[part 1 of 6: packages /MVCU_AutoGenPkg/MVCU/Pck_AutoGen_Sw/ApplicationDataTypes to /MVCU_AutoGenPkg/MVCU/Pck_AutoGen_Sw/Components]
AUTOSAR XML (schema 4-2-2)
package /MVCU_AutoGenPkg/MVCU/Pck_AutoGen_Sw/ApplicationDataTypes
  2084 x app type, all with category=VALUE, sw-calibration-access=READ-ONLY:
    DT_DT_MCUM_CRC_135
    DT_DT_MCUM_RollingCounter_135
    DT_DT_MCUM_LDC_SWInfo
    DT_DT_MCUM_LDC_MTarOut_FA
    DT_DT_MCUM_LDC_MTarOut_RA
    DT_DT_MCUM_LDC_Available_FA
    DT_DT_MCUM_LDC_OperationMode_FA
    DT_DT_MCUM_LDC_Available_RA
    DT_DT_MCUM_LDC_OperationMode_RA
    DT_DT_MCUM_RTE_Exchange_Signal_Status
    DT_DT_MCUM_MTarIn_FA
    DT_DT_MCUM_MTarIn_RA
    DT_DT_MCUM_InputQF_FA
    DT_DT_MCUM_InputQF_RA
    DT_DT_IBC_CRC_136
    DT_DT_IBC_RollingCounter_136
    DT_DT_IBC_ModeMinEDrvTar_FA
    DT_DT_IBC_ModeMinEDrvTar_RA
    DT_DT_IBC_ModeMaxEDrvTar_FA
    DT_DT_IBC_ModeMaxEDrvTar_RA
    DT_DT_IBC_torque_distribution_RA_Vaild
    DT_DT_IBC_torque_distribution_RA
    DT_DT_IBC_mTar_FA
    DT_DT_IBC_mTar_RA
    DT_DT_IBC_iLDC_SWInfo
    DT_DT_IBC_Variant_Signal
    DT_DT_IBC_dTCS_VehBrkCor
    DT_DT_IBC_nTarMax_FA
    DT_DT_IBC_nTarMax_RA
    DT_DT_IBC_nTarMin_FA
    DT_DT_IBC_nTarMin_RA
    DT_DT_EVCC_DCAC_ChgMode
    DT_DT_EVCC_CP_status
    DT_DT_EVCC_CPDutyCycleValue
    DT_DT_EVCC_EVSEMaximumCurrentLimit
    DT_DT_EVCC_EVSEMaximumPowerLimit
    DT_DT_ICU_CRC_24C
    DT_DT_ICU_PHEVMode
    DT_DT_ICU_RollingCounter_24C
    DT_DT_ICU_TotalOdometerkm
    DT_DT_ICU_AccelerationMode
    DT_DT_ICU_REMode
    DT_DT_ICU_CreepMode
    DT_DT_ICU_EnergyRecoveryMode
    DT_DT_MCUS_CRC_DB
    DT_DT_MCUS_Clutch_2_Fault
    DT_DT_MCUS_Clutch_1_Fault
    DT_DT_MCUS_Clutch_2_WarningLevel
    DT_DT_MCUS_Clutch_1_WarningLevel
    DT_DT_MCUS_Clutch_2_Pos
    DT_DT_MCUS_Clutch_1_Pos
    DT_DT_MCUS_RollingCounter_DB
    DT_DT_MCUS_WarningLevel
    DT_DT_MCUS_SelfCheckSts
    DT_DT_MCUS_DrvMotorWorkSts
    DT_DT_MCUS_PowerReduceSts
    DT_DT_MCUS_SystemError
    DT_DT_MCUS_LVSystemError
    DT_DT_MCUS_MotorTempAlarm
    DT_DT_MCUS_HVSystemError
    DT_DT_MCUS_SeriousWarning_Level
    DT_DT_MCUS_CtrlModeVD
    DT_DT_MCUS_WaterPumpLevlReq
    DT_DT_MCUS_MotorTemp
    DT_DT_MCUS_IGBTTemp
    DT_DT_MCUS_InletTemp
    DT_DT_MCUS_DrvMotorRPM
    DT_DT_MCUS_ActualTorqueFB
    DT_DT_MCUS_HWRdcFault
    DT_DT_MCUS_HighVoltPowerOffReq
    DT_DT_MCUS_HVILSts
    DT_DT_MCUS_DragSts
    DT_DT_MCUS_CtrlMode
    DT_DT_MCUS_MILlampReq
    DT_DT_MCUS_DrvMotorRPMVD
    DT_DT_MCUS_ActualTorqueFBVD
    DT_DT_MCUS_MaxTorqueAllow
    DT_DT_MCUS_MaxSpeedAllow
    DT_DT_MCUS_ActiveReleaseSts
    DT_DT_MCUS_MinTorqueAllow
    DT_DT_MCUS_MainWireVolt
    DT_DT_MCUS_MainWireCurr
    DT_DT_MCUS_Clutch_Pos
    DT_DT_MCUS_Clutch_Fault
    DT_DT_MCUS_TMS_FrMotSelfHeatEnSts
    DT_DT_MCUS_TMS_FrMotSelfHeatLvlFb
    DT_DT_MCUS_HeatPwrAval
    DT_DT_DelayIden_Rslt_Avg
    DT_DT_DelayIden_OverRange
    DT_DT_DelayIden_Iden_Finish
    DT_DT_DelayIden_Write_Finish
    DT_DT_DelayIden_Rslt_U
    DT_DT_DelayIden_Rslt_V
    DT_DT_DelayIden_Rslt_W
    DT_DT_GainIden_Is_Samp_U
    DT_DT_GainIden_Rslt_U
    DT_DT_GainIden_OverRange
    DT_DT_GainIden_Is_Samp_V
    DT_DT_GainIden_Rslt_V
    DT_DT_GainIden_Iden_Finish
    DT_DT_GainIden_Is_Samp_W
    DT_DT_GainIden_Rslt_W
    DT_DT_GainIden_Write_Finish
    DT_DT_GainIden_Curr_Peak_U
    DT_DT_GainIden_Curr_Peak_V
    DT_DT_GainIden_Curr_Peak_W
    DT_DT_CurrLoad_CurExt_U
    DT_DT_CurrLoad_CurExt_V
    DT_DT_CurrLoad_CurExt_W
    DT_DT_CurrLoad_offset_Iu
    DT_DT_CurrLoad_offset_Iv
    DT_DT_CurrLoad_offset_Iw
    DT_DT_MCUMR_DelayIden_Rslt_Avg
    DT_DT_MCUMR_DelayIden_OverRange
    DT_DT_MCUMR_DelayIden_Iden_Finish
    DT_DT_MCUMR_DelayIden_Write_Finish
    DT_DT_MCUMR_DelayIden_Rslt_U
    DT_DT_MCUMR_DelayIden_Rslt_V
    DT_DT_MCUMR_DelayIden_Rslt_W
    DT_DT_MCUMR_GainIden_Is_Samp_U
    DT_DT_MCUMR_GainIden_Rslt_U
    DT_DT_MCUMR_GainIden_OverRange
    DT_DT_MCUMR_GainIden_Is_Samp_V
    DT_DT_MCUMR_GainIden_Rslt_V
    DT_DT_MCUMR_GainIden_Iden_Finish
    DT_DT_MCUMR_GainIden_Is_Samp_W
    DT_DT_MCUMR_GainIden_Rslt_W
    DT_DT_MCUMR_GainIden_Write_Finish
    DT_DT_MCUMR_GainIden_Curr_Peak_U
    DT_DT_MCUMR_GainIden_Curr_Peak_V
    DT_DT_MCUMR_GainIden_Curr_Peak_W
    DT_DT_MCUMR_CurrLoad_CurExt_U
    DT_DT_MCUMR_CurrLoad_CurExt_V
    DT_DT_MCUMR_CurrLoad_CurExt_W
    DT_DT_MCUMR_CurrLoad_offset_Iu
    DT_DT_MCUMR_CurrLoad_offset_Iv
    DT_DT_MCUMR_CurrLoad_offset_Iw
    DT_DT_BCM_VCU_Authentication_MAC_B{0..15}
    DT_DT_ECM_UDS_PhyReq_Byte{0..7}
    DT_DT_MCUM_Id_Ref
    DT_DT_MCUM_Iq_Ref
    DT_DT_MCUM_Id_Fb
    DT_DT_MCUM_Iq_Fb
    DT_DT_MCUM_Torque_Ref
    DT_DT_MCUM_R_Id_Ref
    DT_DT_MCUM_R_Iq_Ref
    DT_DT_MCUM_R_Id_Fb
    DT_DT_MCUM_R_Iq_Fb
    DT_DT_MCUM_R_Torque_Ref
    DT_DT_MCUM_Vd_Ref
    DT_DT_MCUM_Vq_Ref
    DT_DT_MCUM_Id_LookUp
    DT_DT_MCUM_Iq_LookUp
    DT_DT_MCUM_Spd_Delta
    DT_DT_MCUM_Us_Out
    DT_DT_MCUM_Torque_PwrEst
    DT_DT_MCUM_UserDefine_50ms
    DT_DT_MCUM_Torque_ExtChar
    DT_DT_MCUM_Damp_CompTorque
    DT_DT_MCUM_Damp_CompCoeff
    DT_DT_MCUM_Damp_State
    DT_DT_MCUM_PWM_State
    DT_DT_MCUM_JuncTemp_Max
    DT_DT_MCUM_JuncLoss_Max
    DT_DT_MCUM_CurrAmp_Comp
    DT_DT_MCUM_CurrTheta_Comp
    DT_DT_MCUM_RawSinCorr
    DT_DT_MCUM_RawCosCorr
    DT_DT_MCUM_LUT_Spd
    DT_DT_MCUM_R_HighVoltPowerOffReq
    DT_DT_MCUM_R_MaxTorqueAllow
    DT_DT_MCUM_R_MaxSpeedAllow
    DT_DT_MCUM_R_MinTorqueAllow
    DT_DT_MCUM_R_MotorTemp
    DT_DT_MCUM_R_IGBTTemp
    DT_DT_MCUM_R_InletTemp
    DT_DT_MCUM_R_HeatPwrAllwd
    DT_DT_MCUM_R_HeatFdBck
    DT_DT_MCUM_R_HeatPwrAct
    DT_DT_MCUM_R_HeatPwrMax
    DT_DT_MCUM_R_HeatPwrAval
    DT_DT_MCUM_R_Vd_Ref
    DT_DT_MCUM_R_Vq_Ref
    DT_DT_MCUM_R_Id_LookUp
    DT_DT_MCUM_R_Iq_LookUp
    DT_DT_MCUM_R_Spd_Delta
    DT_DT_MCUM_R_Us_Out
    DT_DT_MCUM_R_Torque_PwrEst
    DT_DT_MCUM_R_UserDefine_50ms
    DT_DT_MCUM_R_Torque_ExtChar
    DT_DT_MCUM_R_Damp_CompTorque
    DT_DT_MCUM_R_Damp_CompCoeff
    DT_DT_MCUM_R_Damp_State
    DT_DT_MCUM_R_PWM_State
    DT_DT_MCUM_R_JuncTemp_Max
    DT_DT_MCUM_R_JuncLoss_Max
    DT_DT_MCUM_R_CurrAmp_Comp
    DT_DT_MCUM_R_CurrTheta_Comp
    DT_DT_MCUM_R_RawSinCorr
    DT_DT_MCUM_R_RawCosCorr
    DT_DT_MCUM_R_LUT_Spd
    DT_DT_MCUM_R_StatorTemp_1
    DT_DT_MCUM_R_L2TqAct
    DT_DT_MCUM_R_EOPSw
    DT_DT_MCUM_R_StatorTemp_2
    DT_DT_MCUM_R_IGBTTemp_U
    DT_DT_MCUM_R_IGBTTemp_V
    DT_DT_MCUM_R_IGBTTemp_W
    DT_DT_MCUM_R_Power_15V
    DT_DT_MCUM_R_Offset_IU
    DT_DT_MCUM_R_Offset_IV
    DT_DT_MCUM_R_Offset_IW
    DT_DT_MCUM_R_MainSt_State
    DT_DT_MCUM_R_Derate_Reason
    DT_DT_MCUM_R_PWM_Freq_kHz
    DT_DT_MCUM_R_PWMEn_State
    DT_DT_MCUM_R_DrvPwrEn_Out_State
    DT_DT_MCUM_R_NVM_RslvrZeroRFault
    DT_DT_MCUM_R_Rotor_Position
    DT_DT_MCUM_R_PosTransduserFaultCode
    DT_DT_MCUM_R_NVM_RslvrDirRFault
    DT_DT_MCUM_R_NVM_RslvrDelayRFault
    DT_DT_MCUM_R_NVM_RslvrParamRFault
    DT_DT_MCUM_R_NVM_HallGainRFault
    DT_DT_MCUM_R_NVM_HallDelayRFault
    DT_DT_MCUM_R_NVM_IGBTTypeRFault
    DT_DT_MCUM_R_ASC_EntryCount
    DT_DT_MCUM_R_Spd_Turn
    DT_DT_MCUM_R_LUT_Spd_Max
    DT_DT_MCUM_R_EOP_Speed
    DT_DT_MCUM_R_EOP_IqFb
    DT_DT_MCUM_R_EOP_IqRef
    DT_DT_MCUM_R_EOP_DCVolt
    DT_DT_MCUM_R_EOP_DCCurr
    DT_DT_MCUM_R_EOP_Temp
    DT_DT_MCUM_R_EOP_State
    DT_DT_MCUM_R_EOP_FaultCode
    DT_DT_MCUM_R_HWFault_RstCnt
    DT_DT_MCUM_R_HWFoB_RstCnt
    DT_DT_MCUM_R_HWFoT_RstCnt
    DT_DT_MCUM_R_HWDrvUV_RstCnt
    DT_DT_MCUM_R_HWRdc_RstCnt
    DT_DT_MCUM_R_HWOC_RstCnt
    DT_DT_MCUM_R_HWOV_RstCnt
    DT_DT_MCUM_R_L2agRtrElecDiff
    DT_DT_MCUM_R_500usOverTime_Cnt
    DT_DT_MCUM_R_5msOverTime_Cnt
    DT_DT_MCUM_R_CpldRest_TimeOut_flag
    DT_DT_MCUM_R_DrvPCBCurr
    DT_DT_MCUM_R_EOL_StateMachine
    DT_DT_MCUM_R_CpldRest_ASC_Flag
    DT_DT_MCUM_R_LimSpdTorFlag
    DT_DT_MCUM_R_PWM_Err_Count
    DT_DT_MCUM_R_RDC_Reset_Count
    DT_DT_MCUM_R_ASC_Stop_Flag
    DT_DT_MCUM_R_ASC_Soft_Exiting_Flag
    DT_DT_MCUM_R_Vbus_ServeLowChkEn
    DT_DT_MCUM_R_EOP_BlockErr_IsLim_Flag
    DT_DT_MCUM_R_IdqErrCount
    DT_DT_MCUM_R_MotSelfHeat_EnSts
    DT_DT_MCUM_R_MotBlockHeat_LvlFb
    DT_DT_MCUM_R_MotRotaryHeat_LvlFb
    DT_DT_MCUM_R_MotSelfHeat_DropLvlFb
    DT_DT_MCUM_R_MotSelfHeat_DropLvlRsn
    DT_DT_MCUM_R_MotBlockHeat_CurAngle
    DT_DT_MCUM_R_MotBlockHeat_CurMag
    DT_DT_MCUM_R_UserDefine_Byte{1..4}
    DT_DT_MCUM_R_UserDefine_Word{1..3}
    DT_DT_VCU_MotSelfHeatPwrFb
    DT_DT_VCU_MotSelfHeatLvlFb
    DT_DT_VCU_MCUMWaterPumpLevlReq
    DT_DT_VCU_MCUSWaterPumpLevlReq
    DT_DT_VCU_HeatPwrAval
    DT_DT_VCU_MotSelfHeatAllwd
    DT_DT_VCU_MMotSelfHeatEnReq
    DT_DT_VCU_MMotSelfHeatLvlReq
    DT_DT_VCU_SMotSelfHeatEnReq
    DT_DT_VCU_SMotSelfHeatLvlReq
    DT_DT_Debug_MCU_CRC_CA
    DT_DT_Debug_MCU_RollingCounter_CA
    DT_DT_Debug_MCU_WarningLevel
    DT_DT_Debug_MCU_SelfCheckSts
    DT_DT_Debug_MCU_DrvMotorWorkSts
    DT_DT_Debug_MCU_PowerReduceSts
    DT_DT_Debug_MCU_DrvMotorRPM
    DT_DT_Debug_MCU_ActualTorqueFB
    DT_DT_Debug_MCU_HWRdcFault
    DT_DT_Debug_MCU_HighVoltPowerOffReq
    DT_DT_Debug_MCU_HVILSts
    DT_DT_Debug_MCU_DragSts
    DT_DT_Debug_MCU_CtrlMode
    DT_DT_Debug_MCU_MILlampReq
    DT_DT_Debug_MCU_DrvMotorRPMVD
    DT_DT_Debug_MCU_ActualTorqueFBVD
    DT_DT_Debug_MCU_MaxTorqueAllow
    DT_DT_Debug_MCU_MaxSpeedAllow
    DT_DT_Debug_MCU_ActiveReleaseSts
    DT_DT_Debug_MCU_DCChargRelaySts
    DT_DT_Debug_MCUM_MinTorqueAllow
    DT_DT_Debug_MCU_MainWireVolt
    DT_DT_Debug_MCU_MainWireCurr
    DT_DT_Debug_MCUM_TMS_MotSelfHeatEnSts
    DT_DT_Debug_MCUM_TMS_MotSelfHeatLvlFb
    DT_DT_Debug_MCUM_RPowerReduceSts
    DT_DT_Debug_MCUM_HeatPwrAval
    DT_DT_Debug_MCUM_RCtrlMode
    DT_DT_Debug_MCUM_RWarningLevel
    DT_DT_Debug_MCUM_RSelfCheckSts
    DT_DT_Debug_MCUM_RDrvMotorWorkSts
    DT_DT_Debug_MCUM_RCtrlModeVD
    DT_DT_Debug_MCUM_RHWRdcFault
    DT_DT_Debug_MCUM_RDrvMotorRPMVD
    DT_DT_Debug_MCUM_RActualTorqueFBVD
    DT_DT_Debug_MCUM_RDrvMotorRPM
    DT_DT_Debug_MCUM_RActualTorqueFB
    DT_DT_IBS_CRC_225
    DT_DT_IBS_RollingCounter_225
    DT_DT_IBS_Warning_Level
    DT_DT_ADDC_CRC_84
    DT_DT_ADDC_APS_AVHReq
    DT_DT_ADDC_APS_HoldSts
    DT_DT_ADDC_APSTargetTrqBrkVD
    DT_DT_ADDC_APSTargetTrqBrk
    DT_DT_ADDC_APSTargetTrqVD
    DT_DT_ADDC_APSTargetTrq
    DT_DT_ADDC_safety_valid
    DT_DT_ADDC_rearsafety_level
    DT_DT_ADDC_frontsafety_level
    DT_DT_ADDC_rightsafety_level
    DT_DT_ADDC_leftsafety_level
    DT_DT_ADDC_RollingCounter_84
    DT_DT_ADDC_APS_EnableReq
    DT_DT_ADDC_APS_WorkSts
    DT_DT_ADDC_APS_PDCVehicleDirectCtlVD
    DT_DT_ADDC_APS_VehicleSpeedCtlVD
    DT_DT_ADDC_APS_PDC_VehicleDirectCtl
    DT_DT_ADDC_APS_PDC_SWAngCtl
    DT_DT_ADDC_APS_ParkingReq
    DT_DT_ADDC_APS_EmergenceBrake
    DT_DT_ADDC_APS_TargetAccVD
    DT_DT_ADDC_APS_TargetAcc
    DT_DT_ADDC_APS_VehicleSpeedCtl
    DT_DT_ADDC_APS_DecToStop
    DT_DT_ADDC_APS_Driveoff_Request
    DT_DT_ADDC_APS_FuncType
    DT_DT_ADDC_APS_Available
    DT_DT_IVI_Year
    DT_DT_IVI_Month
    DT_DT_IVI_Data
    DT_DT_IVI_Hour
    DT_DT_IVI_Minute
    DT_DT_IVI_Second
    DT_DT_DCDC_CRC_324
    DT_DT_DCDC_RollingCounter_324
    DT_DT_DCDC_WorkSts
    DT_DT_DCDC_Under_Output_Voltage
    DT_DT_DCDC_Over_Output_Voltage
    DT_DT_DCDC_Under_Input_Voltage
    DT_DT_DCDC_Over_Input_Voltage
    DT_DT_DCDC_Over_Input_Current
    DT_DT_DCDC_Real_Output_Current
    DT_DT_DCDC_Real_Output_Voltage
    DT_DT_DCDC_Real_Input_Current
    DT_DT_DCDC_Real_Input_Voltage
    DT_DT_DCDC_Derating
    DT_DT_DCDC_Hardware_Fault_Flag
    DT_DT_CDU_ACChg_HIVSts
    DT_DT_CDU_OBC_OverTemp
    DT_DT_CDU_SelfCheckSt
    DT_DT_CDU_HV_HIVSts
    DT_DT_FSC_CRC_142
    DT_DT_FSC_RollingCounter_142
    DT_DT_FSC_LCC_Mode
    DT_DT_MotClb_FaultCode{1..8}
    DT_DT_MotClb_OfsApply
    DT_DT_MCUMR_MotClb_FaultCode{1..8}
    DT_DT_MCUMR_MotClb_OfsApply
    DT_DT_EOL_ModeCMD_Data{0..5}
    DT_DT_EOL_ModeCMD_Enable
    DT_DT_EOL_ModeCMD_Check
    DT_DT_EOL_GainIden_UsApply
    DT_DT_EOL_MotClb_CtrlMode
    DT_DT_MotClb_OfsSet
    DT_DT_EOL_MotClb_IsCMD
    DT_DT_EOL_MotClb_ThetaCMD
    DT_DT_EOL_frqsync
    DT_DT_EOL_MotClb_Enable
    DT_DT_EOL_ActiveReleaseCmd
    DT_DT_MotClb_OfsAdjEn
    DT_DT_EOL_Asc_CMD
    DT_DT_EOL_PosDly_SnsrSupplier
    DT_DT_FstRcrd_Enable
    DT_DT_GainIden_CurrRMS_Ref_U
    DT_DT_GainIden_CurrRMS_Ref_V
    DT_DT_GainIden_CurrRMS_Ref_W
    DT_DT_MCUMR_EOL_GainIden_UsApply
    DT_DT_MCUMR_EOL_MotClb_CtrlMode
    DT_DT_MCUMR_MotClb_OfsSet
    DT_DT_MCUMR_EOL_MotClb_IsCMD
    DT_DT_MCUMR_EOL_MotClb_ThetaCMD
    DT_DT_MCUMR_EOL_frqsync
    DT_DT_MCUMR_EOL_MotClb_Enable
    DT_DT_MCUMR_EOL_ActiveReleaseCmd
    DT_DT_MCUMR_MotClb_OfsAdjEn
    DT_DT_MCUMR_EOL_Asc_CMD
    DT_DT_MCUMR_EOL_PosDly_SnsrSupplier
    DT_DT_MCUMR_FstRcrd_Enable
    DT_DT_MCUMR_GainIden_CurrRMS_Ref_U
    DT_DT_MCUMR_GainIden_CurrRMS_Ref_V
    DT_DT_MCUMR_GainIden_CurrRMS_Ref_W
    DT_DT_MCUS_CRC_14
    DT_DT_MCUS_RollingCounter_14
    DT_DT_MCUS_DrvMotorRPM_prvt
    DT_DT_MCUS_ActualTorqueFB_prvt
    DT_DT_MCUS_DrvMotorRPMVD_prvt
    DT_DT_MCUS_ActualTorqueFBVD_prvt
    DT_DT_U16_CMD{1..4}
    DT_DT_S16_CMD{1..4}
    DT_DT_R16_CMD{1..4}
    DT_DT_U8_CMD{1..8}
    DT_DT_OBC_CRC_316
    DT_DT_OBC_RollingCounter_316
    DT_DT_OBC_WorkSts
    DT_DT_OBC_StartSts
    DT_DT_OBC_DCSts
    DT_DT_OBC_ACChargeOutputSts
    DT_DT_OBC_DCVolt
    DT_DT_OBC_HardwareSts
    DT_DT_OBC_DCCurr
    DT_DT_OBC_ACVolt
    DT_DT_OBC_ACCurr
    DT_DT_OBC_CCConnectSts
    DT_DT_OBC_CPDutyCycleFault
    DT_DT_OBC_CPDutyCycleValue
    DT_DT_OBC_ACMaxPower
    DT_DT_OBC_ACPowerState
    DT_DT_LMC_CRC_FA
    DT_DT_LMC_RollingCounter_FA
    DT_DT_LMC_EngTorqDec_Main
    DT_DT_LMC_EngTorqDecActive_Main
    DT_DT_LMC_AMM_St
    DT_DT_LMC_EngTorqInc_Main
    DT_DT_LMC_EngTorqIncActive_Main
    DT_DT_LMC_EngTorqDec_Sub
    DT_DT_LMC_EngTorqDecActive_Sub
    DT_DT_LMC_EngTorqInc_Sub
    DT_DT_LMC_EngTorqIncActive_Sub
    DT_DT_LMC_CRC_18C
    DT_DT_LMC_RollingCounter_18C
    DT_DT_LMC_TqTotalBrakeTorque
    DT_DT_LMC_TqTotalBrakeTorque_Valid
    DT_DT_LMC_CmpUTurnLockwhists
    DT_DT_GW_CRC_3B1
    DT_DT_GW_RollingCounter_3B1
    DT_DT_GW_ACU_FLSeatBeltRSt
    DT_DT_GW_ACU_FRSeatBeltRSt
    DT_DT_GW_IBC_EPB_Status
    DT_DT_GW_ACU_TotalCrashOutputSts
    DT_DT_GW_BZCU_DCChgExitTemp_Pos
    DT_DT_GW_BZCU_DCChgExitTemp_Neg
    DT_DT_GW_BZCU_ACChgExitTemp_Pos
    DT_DT_GW_BZCU_FuelTankSts
    DT_DT_GW_BZCU_LBMS_VoltA
    DT_DT_GW_BZCU_ACChgExitTemp_Neg
    DT_DT_GW_BZCU_FuelTankStsLockSts
    DT_DT_GW_BZCU_FuelTankLockCtrl
    DT_DT_GW_BZCU_ACChgLockSts
    DT_DT_GW_RZCU_Cabin_220Vconnect_Sts
    DT_DT_GW_BZCU_Cab_220VRelay_CtrlSts
    DT_DT_GW_BZCU_Cab_PDU220VRelay_CtrlSts
    DT_DT_GW_BZCU_Cabin_220VRelay_CtrlSts
    DT_DT_GW_BZCU_Cab_220Vconnect_Sts
    DT_DT_GW_TBOXSOC_Altitude
    DT_DT_VCU_EolCfg_ESC
    DT_DT_VCU_IMMOKeyWriteCnt
    DT_DT_VCU_AbStartupFlag
    DT_DT_VCU_AbResetFlag
    DT_DT_VCU_AbResetlnitFinish
    DT_DT_VCU_EolCfg_EPB
    DT_DT_VCU_EolCfg_AEB
    DT_DT_VCU_EolCfg_InverterFunc
    DT_DT_VCU_EolCfg_APS
    DT_DT_VCU_EolCfg_VehiModels
    DT_DT_VCU_EolCfg_SpdLmtVal
    DT_DT_VCU_EolCfg_WheelType
    DT_DT_VCU_EolCfg_Curise
    DT_DT_VCU_REStartReq
    DT_DT_VCU_REStopReq
    DT_DT_VCU_EolCfg_VehiType
    DT_DT_VCU_EolCfg_MotPwr
    DT_DT_VCU_Vehicle_NVHPwrLimitVal
    DT_DT_VCU_EolCfg_MotDrvStructure
    DT_DT_VCU_WLTCModeFlag
    DT_DT_VCU_EolCfg_RudderDir
    DT_DT_VCU_EolCfg_DCChgRelayPos
    DT_DT_VCU_EolCfg_FPTCIL
    DT_DT_VCU_PWakeupSt
    DT_DT_VCU_SpdLimitReason
    DT_DT_BSW_VertifySts
    DT_DT_VCU_InterAllowEngStart
    DT_DT_VCU_EngineOff_Flag
    DT_DT_VCU_EngineStopAllow
    DT_DT_VCU_EmergencyStopReq
    DT_DT_VCU_EngineAllowStop
    DT_DT_VCU_REVehiWheelTrqReq
    DT_DT_VCU_REHighPerformVehiPwr
    DT_DT_VCU_REPwrDampingFactor
    DT_DT_VCU_REDrvTarPwrFit
    DT_DT_VCU_AdditionalPwrVal
    DT_DT_VCU_VehichRealPwDown
    DT_DT_VCU_IMMOStsResult
    DT_DT_VCU_IMMOStateMachine
    DT_DT_VCU_ShowCarModeNvmResult
    DT_DT_VCU_DeliveryModeNvmData
    DT_DT_VCU_AccPedFaultLvNvmResult
    DT_DT_VCU_VehicleConfigNvmResult
    DT_DT_VCU_EngRunTimeNvmResult
    DT_DT_VCU_FuelConsumption
    DT_DT_VCU_SVSLamp
    DT_DT_VCU_MilLamp
    DT_DT_VCU_SinglePedalSts_ID514
    DT_DT_VCU_GearLevelPosFault_ID514
    DT_DT_VCU_EngineStartFailure_ID514
    DT_DT_VCU_ParkBeforeFuelup
    DT_DT_VCU_REsystemFaultSts_ID514
    DT_DT_VCU_EngineRunAllowFlg_ID514
    DT_DT_VCU_InverterTip
    DT_DT_VCU_EMSRepairModeSts
    DT_DT_VCU_FuelTankFlapSts
    DT_DT_VCU_REsystemSts_ID514
    DT_DT_VCU_PowerModeAllow
    DT_DT_VCU_PowerModeSwitchMsg
    DT_DT_VCU_HighVoltFailed_M
    DT_DT_VCU_HighVoltFailed_S
    DT_DT_VCU_BrakeBeforeGear
    DT_DT_VCU_ParkBeforeGear
    DT_DT_VCU_GearBeforDriving
    DT_DT_VCU_UnlockBeforeDriving
    DT_DT_VCU_PreventSliding
    DT_DT_VCU_MMErrorSts
    DT_DT_VCU_ShowCarModeSts
    DT_DT_VCU_PGearFlashSts
    DT_DT_VCU_ACConnectSts
    DT_DT_VCU_DcChgPwrSts
    DT_DT_VCU_DriverAssistProhibitSts_ID514
    DT_DT_VCU_MilLampRequest_ID514
    DT_DT_VCU_CcmHvilInSigFreq_FB
    DT_DT_VCU_CcmHvilInSigDuty_FB
    DT_DT_VCU_FuelDectionModeSts
    DT_DT_VCU_EnergyCtrlMode
    DT_DT_VCU_VehSpdLimtRemind_ID514
    DT_DT_VCU_TurtleLamp
    DT_DT_VCU_EngLongTimeStartReq
    DT_DT_GW_CRC_13A
    DT_DT_GW_RollingCounter_13A
    DT_DT_GW_IBC_VehicleSpeed
    DT_DT_GW_IBC_VehicleSpeedVD
    DT_DT_GW_IBC_AVHStatus
    DT_DT_GW_IBC_RAB_Avatiable
    DT_DT_GW_IBC_RAB_Active
    DT_DT_GW_IBC_FLWheelSpeedKPH
    DT_DT_GW_IBC_FRWheelSpeedKPH
    DT_DT_GW_IBC_RLWheelSpeedKPH
    DT_DT_GW_IBC_RRWheelSpeedKPH
    DT_DT_GW_IBC_FLWheelDirection
    DT_DT_GW_IBC_FRWheelDirection
    DT_DT_GW_IBC_RLWheelDirection
    DT_DT_GW_IBC_RRWheelDirection
    DT_DT_GW_IBC_FLWheelSpeedVD
    DT_DT_GW_IBC_FRWheelSpeedVD
    DT_DT_GW_IBC_RLWheelSpeedVD
    DT_DT_GW_IBC_RRWheelSpeedVD
    DT_DT_GW_IBC_PlungerPressure_Q
    DT_DT_GW_IBC_PlungerPressure
    DT_DT_CCM_Volt
    DT_DT_CCM_RollingCounter_36A
    DT_DT_CCM_BaseState
    DT_DT_CCM_Power
    DT_DT_CCM_APTC_BscSts
    DT_DT_CCM_APTC_Power
    DT_DT_IBC_CRC_227
    DT_DT_IBC_RollingCounter_227
    DT_DT_IBC_EPB_FailStatus
    DT_DT_IBC_EPB_Status
    DT_DT_IBC_EPB_DrumMode
    DT_DT_IBC_EPB_AchievedClampForce
    DT_DT_IBC_EPB_FailureLamp
    DT_DT_IBC_EPB_ActuatorStateLeft
    DT_DT_IBC_EPB_ActuatorStateRight
    DT_DT_IBC_EPB_HostAvailabilityLeft
    DT_DT_IBC_EPB_HostAvailabilityRight
    DT_DT_Harness_igbt_temp{1..3}
    DT_DT_Harness_CoolWaterTemp
    DT_DT_Harness_V_DC
    DT_DT_Harness_PWM_DIR
    DT_DT_Harness_HVIL_State
    DT_DT_Harness_crash_err_flag
    DT_DT_Harness_KeyON
    DT_DT_Harness_HWRdc
    DT_DT_Harness_HWFoT
    DT_DT_Harness_HWVoltLower
    DT_DT_Harness_HWFoB
    DT_DT_Harness_MotorTemp1
    DT_DT_Harness_MotorTemp2
    DT_DT_Harness_I_U
    DT_DT_Harness_I_W
    DT_DT_Harness_I_V
    DT_DT_Harness_HVRelayPosVolt
    DT_DT_MCUMR_Harness_igbt_temp{1..3}
    DT_DT_MCUMR_Harness_CoolWaterTemp
    DT_DT_MCUMR_Harness_V_DC
    DT_DT_MCUMR_Harness_PWM_DIR
    DT_DT_MCUMR_Harness_HWRdc
    DT_DT_MCUMR_Harness_HWFoT
    DT_DT_MCUMR_Harness_HWVoltLower
    DT_DT_MCUMR_Harness_HWFoB
    DT_DT_MCUMR_Harness_MotorTemp1
    DT_DT_MCUMR_Harness_MotorTemp2
    DT_DT_MCUMR_Harness_I_U
    DT_DT_MCUMR_Harness_I_W
    DT_DT_MCUMR_Harness_I_V
    DT_DT_BCM_CRC_290
    DT_DT_BCM_RRDoorSts_ID290_CCAN
    DT_DT_BCM_RLDoorSts_ID290_CCAN
    DT_DT_BCM_RollingCounter_290
    DT_DT_BCM_HazardSwtSts
    DT_DT_BCM_DrOC_PPD_Status
    DT_DT_BCM_FLOC_PPD_Status
    DT_DT_BCM_FROC_PPD_Status
    DT_DT_BCM_DriverDoorSts_ID290_CCAN
    DT_DT_BCM_DriverDoorSts_VD
    DT_DT_BCM_FLDoorSts_ID290_CCAN
    DT_DT_BCM_FRDoorSts_ID290_CCAN
    DT_DT_BCM_BackDoorSts_ID290_CCAN
    DT_DT_BCM_FrontCoverSts
    DT_DT_BCM_HazardSwtOpenSts
    DT_DT_BCM_BrakeFluidLevel
    DT_DT_BCM_ON2BRelaySts_ID290_CCAN
    DT_DT_BCM_ON2CRelaySts_ID290_CCAN
    DT_DT_BCM_AlarmMode_C
    DT_DT_VCU_CRC_13
    DT_DT_VCU_RollingCounter_13
    DT_DT_VCU_SDrvRequestTorque_prvt
    DT_DT_VCU_SDrvRequestTorqueVD_prvt
    DT_DT_VCU_MCUSDampgLmtFactor_prvt
    DT_DT_VCU_VehicleDirectS_prvt
    DT_DT_VCU_VehicleDirectS_VD_prvt
    DT_DT_VCU_MCUSMaxPosDampgTrq_prvt
    DT_DT_VCU_MCUSMaxNegDampgTrq_prvt
    DT_DT_EOL_CRC_13B
    DT_DT_EOL_RollingCounter_13B
    DT_DT_EOL_VehicleSts
    DT_DT_EOL_GearLevelPosSts
    DT_DT_EOL_GearLeverValid
    DT_DT_EOL_AccPedalValid
    DT_DT_EOL_ThrottlePosition
    DT_DT_EOL_RMCUActiveReleaseCmd
    DT_DT_EOL_VehicleDirect
    DT_DT_EOL_SuppressJitterRMCURequest
    DT_DT_EOL_RDrvControlMode
    DT_DT_EOL_BrakePedalValue
    DT_DT_EOL_RMCUMaxDischargePower
    DT_DT_EOL_RMCUMaxChargePower
    DT_DT_EOL_RDrvRequestTorque
    DT_DT_EOL_RDrvRequesSpeed
    DT_DT_EOL_FDrvRequestTorque
    DT_DT_EOL_FDrvRequesSpeed
    DT_DT_EOL_FVehicleSts
    DT_DT_EOL_FDrvControlMode
    DT_DT_EOL_ON2BRelayReq
    DT_DT_EOL_VehicleDirectVD
    DT_DT_EOL_RDrvControlModeVD
    DT_DT_EOL_RDrvRequestTorqueVD
    DT_DT_EOL_RDrvRequesSpeedVD
    DT_DT_EOL_FDrvRequestTorqueVD
    DT_DT_EOL_FDrvRequesSpeedVD
    DT_DT_EOL_FDrvControlModeVD
    DT_DT_EOL_MCUMDampgLmtFactor
    DT_DT_EOL_VCU_BoostMode_Fail
    DT_DT_EOL_VCU_BoostModeSts
    DT_DT_EOL_MCUMMaxPosDampgTrq
    DT_DT_EOL_MCUMMaxNegDampgTrq
    DT_DT_TMS_MilLampReq
    DT_DT_EMS_CRC_BE
    DT_DT_EMS_RollingCounter_BE
    DT_DT_EMS_EngineSts
    DT_DT_ECM_FaultLevel
    DT_DT_ECM_ActualEngineTorqueValid
    DT_DT_ECM_EngineTorqueLoss
    DT_DT_ECM_ActualEngineTorque
    DT_DT_ECM_EngineTorqueMax
    DT_DT_ECM_EngineTorqueMin
    DT_DT_ECM_EngineSpeed
    DT_DT_ECM_EngineSpeedValid
    DT_DT_ECM_EngineStopAllow
    DT_DT_ECM_EngineOilPressureLow
    DT_DT_ECM_EngineFuleCutoffSts
    DT_DT_ECM_EngineStartedCompleted
    DT_DT_ECM_CatalystWarmUpSts
    DT_DT_ECM_CatalystWarmUpReq
    DT_DT_ECM_IdleTargetSpeed
    DT_DT_ECM_IdleActive
    DT_DT_ECM_EngineStartReq
    DT_DT_ECM_EngineStopInhibit
    DT_DT_ECM_GPFRegenlamp
    DT_DT_ECM_EngineCoolantTemp
    DT_DT_ECM_EngineCoolantTempValid
    DT_DT_ECM_FVVSts
    DT_DT_ECM_learningReq
    DT_DT_ECM_EngineIdleStateRequest
    DT_DT_ECM_EngineDFCOConditionRequest
    DT_DT_ECM_GPFRegenReq
    DT_DT_ECM_SVSLampRequest
    DT_DT_ECM_TankPressure
    DT_DT_ECM_TankPressureValid
    DT_DT_ECM_MilLampRequest
    DT_DT_ECM_ToothlearningSucValid
    DT_DT_ECM_FuelCloseLoopSts
    DT_DT_ECM_RestrictorOpenValue
    DT_DT_ECM_FuelLevelSensorValid
    DT_DT_ECM_FuelLevel
    DT_DT_ECM_SelfCheckSt
    DT_DT_ECM_PCVPipeDiagReq
    DT_DT_ECM_CalculatedLoad
    DT_DT_ECM_FuelConsumption
    DT_DT_ECM_AirPressure
    DT_DT_ECM_FanSts
    DT_DT_EPS_CRC_18D
    DT_DT_EPS_RollingCounter_18D
    DT_DT_EPS_Fault
    DT_DT_EPS_CalibrationSts
    DT_DT_EPS_FailureSts
    DT_DT_EPS_SteeringAngleValidData
    DT_DT_EPS_SteeringAngleSpeedValidData
    DT_DT_EPS_SteerWheelAngle
    DT_DT_EPS_SteerWheelRotSpd
    DT_DT_EPS_SelfCheckSt
    DT_DT_EPS_AssistanceSts
    DT_DT_GCU_CRC_BD
    DT_DT_GCU_EngineCylinderDeactivationStatus
    DT_DT_GCU_EngineFuelInhibitReq
    DT_DT_GCU_RollingCounter_BD
    DT_DT_GCU_MainWireCurr
    DT_DT_GCU_MainWireVolt
    DT_DT_GCU_SystemWarning
    DT_DT_GCU_MILlampReq
    DT_DT_GCU_MoterTemp
    DT_DT_GCU_Temp
    DT_DT_GCU_SelfCheck
    DT_DT_GCU_Warning_Level
    DT_DT_GCU_HVILSts
    DT_DT_GCU__PowerReduceSts
    DT_DT_GCU_ActualMotorRPM_VD
    DT_DT_GCU_ActualMotorTorque_VD
    DT_DT_GCU_ActualMotorTorque
    DT_DT_GCU_MaxTorque
    DT_DT_GCU_ActiveReleaseFB
    DT_DT_GCU_MAXPower
    DT_DT_GCU_TransientPower
    DT_DT_GCU_HVOffReq
    DT_DT_GCU_ControlMode
    DT_DT_GCU_Operating_Mode
    DT_DT_GCU_ActualMotorRPM
    DT_DT_BMS_WkupVolt_DC12V
    DT_DT_BMS_WkupVolt_AC12V
    DT_DT_BMS_HVPackPosRelayExternalVolt
    DT_DT_BMS_SOC_target
    DT_DT_BMS_CorrectSOEPer
    DT_DT_BMS_SOCModifyFlag
    DT_DT_BMS_BMU_SoftwareVersion
    DT_DT_VCU_VehicleSpdDirect
    DT_DT_VCU_ADM_ActualMode
    DT_DT_VCU_ADM_MainMode
    DT_DT_VCU_DeliveryModeSts
    DT_DT_VCU_VehSpdLimtRemind
    DT_DT_VCU_SinglePedalSts
    DT_DT_VCU_GearLvrChangeSts
    DT_DT_VCU_HighVoltSysSts
    DT_DT_VCU_ChrgDischrgFunSts
    DT_DT_VCU_CalibrationVersion
    DT_DT_VCU_CalibrationNumber
    DT_DT_VCU_VehicleNegTrqRspdSts
    DT_DT_VCU_SlopeEst
    DT_DT_VCU_SlopeEst_Valid
    DT_DT_VCU_WheelTrqType
    DT_DT_VCU_DriverAssistProhibitSts
    DT_DT_VCU_VacumRlySts
    DT_DT_VCU_DriveSHVILSts
    DT_DT_VCU_DriveMHVILSts
    DT_DT_VCU_DCChgHVILSts
    DT_DT_VCU_ACChgHVILSts
    DT_DT_VCU_CCMHVILSts
    DT_DT_VCU_SystemError
    DT_DT_VCU_AccPedalFaultLV
    DT_DT_VCU_HVILSysSts
    DT_DT_VCU_VacuumDegree
    DT_DT_VCU_LPedalModeSts
    DT_DT_VCU_LVSystemError
    DT_DT_VCU_HVSystemError
    DT_DT_VCU_OpeartingMode
    DT_DT_VCU_EnergyMode
    DT_DT_VCU_GearLevelPosFault
    DT_DT_VCU_BrakeSwitchSts
    DT_DT_VCU_SpdLimModeSts
    DT_DT_VCU_TrqDstrbutnPrio
    DT_DT_VCU_TrqDstrbutnTransferSts
    DT_DT_VCU_MCUMDiffProtectSts
    DT_DT_VCU_MCUSDiffProtectSts
    DT_DT_ICU_CRC_332
    DT_DT_ICU_RollingCounter_332
    DT_DT_ICU_AEB_SW
    DT_DT_ICU_ISA_controlSW
    DT_DT_ICU_SLIF_SW
    DT_DT_ICU_SLWF_SW
    DT_DT_TMS_MainMotPumpSpdResp
    DT_DT_TMS_MainMotPump_Operation_Temp
    DT_DT_TMS_MainMotPump_Operation_Current
    DT_DT_TMS_MainMotPump_Supplied_Voltage
    DT_DT_TMS_MainMotPumpErrSts
    DT_DT_IBC_CRC_184
    DT_DT_IBC_RollingCounter_184
    DT_DT_IBC_FLWheelSpeedKPH
    DT_DT_IBC_FRWheelSpeedKPH
    DT_DT_IBC_RLWheelSpeedKPH
    DT_DT_IBC_RRWheelSpeedKPH
    DT_DT_IBC_FLWheelDirection
    DT_DT_IBC_FRWheelDirection
    DT_DT_IBC_RLWheelDirection
    DT_DT_IBC_RRWheelDirection
    DT_DT_IBC_FLWheelSpeedVD
    DT_DT_IBC_FRWheelSpeedVD
    DT_DT_IBC_RLWheelSpeedVD
    DT_DT_IBC_RRWheelSpeedVD
    DT_DT_IBC_FLWheelSpeedRC
    DT_DT_IBC_FRWheelSpeedRC
    DT_DT_IBC_RLWheelSpeedRC
    DT_DT_IBC_RRWheelSpeedRC
    DT_DT_IBC_DiscTemperatureFL
    DT_DT_IBC_DiscTemperatureFLVD
    DT_DT_IBC_DiscTemperatureFR
    DT_DT_IBC_DiscTemperatureFRVD
    DT_DT_IBC_DiscTemperatureRL
    DT_DT_IBC_DiscTemperatureRLVD
    DT_DT_IBC_DiscTemperatureRR
    DT_DT_IBC_DiscTemperatureRRVD
    DT_DT_IBC_CRC_183
    DT_DT_IBC_RollingCounter_183
    DT_DT_IBC_RecuBrakeTorqueRequest
    DT_DT_IBC_RecuBrakeTorqueRequest_Q
    DT_DT_IBC_sOutputRodDriverPer_Q
    DT_DT_IBC_BrakePedalApplied_Q
    DT_DT_IBC_HydraTorqTgtAct_Q
    DT_DT_IBC_HydraTorqTgtAct
    DT_DT_IBC_BrakePedalApplied
    DT_DT_IBC_sOutputRodDriverPer
    DT_DT_IBC_HydraTorqAvailable
    DT_DT_IBC_CtrlMode
    DT_DT_IBC_QDC_HydraTorqTgt
    DT_DT_IBC_InPutRodDriver
    DT_DT_IBC_InPutRodDriver_Q
    DT_DT_IBC_SystemAssistedStatus
    DT_DT_IBC_EngTorq_VLC_Vaild
    DT_DT_IBC_EngTorq_VLC
    DT_DT_IBC_BrkTorq_VLC
    DT_DT_IBC_BrkTorq_VLC_Vaild
    DT_DT_IBC_CRC_186
    DT_DT_IBC_RollingCounter_186
    DT_DT_IBC_WheelPressureReliabilityFL
    DT_DT_IBC_WheelPressureReliabilityFR
    DT_DT_IBC_WheelPressureReliabilityRL
    DT_DT_IBC_WheelPressureReliabilityRR
    DT_DT_IBC_WheelCylinderPressure_FL
    DT_DT_IBC_WheelCylinderPressure_FR
    DT_DT_IBC_WheelCylinderPressure_RL
    DT_DT_IBC_WheelCylinderPressure_RR
    DT_DT_IBC_WheelSlipFLVD
    DT_DT_IBC_WheelSlipFRVD
    DT_DT_IBC_WheelSlipRLVD
    DT_DT_IBC_WheelSlipRRVD
    DT_DT_IBC_WheelSlipFL
    DT_DT_IBC_WheelSlipFR
    DT_DT_IBC_WheelSlipRL
    DT_DT_IBC_WheelSlipRR
    DT_DT_IBC_Slop_Pencent
    DT_DT_PTC_BscSts
    DT_DT_PTC_RollingCounter_367
    DT_DT_PTC_Fault
    DT_DT_PTC_Power
    DT_DT_PTC_HV_interlock_faultSt
    DT_DT_VCU_FaultData{0..31}
    DT_DT_GW_TCM_CRC_30B
    DT_DT_GW_TCM_RollingCounter_30B
    DT_DT_GW_TCM_ParkingSwSts
    DT_DT_GW_TCM_STATUS_Park
    DT_DT_GW_TCM_Counter_Park
    DT_DT_GW_TCM_CRC_Park
    DT_DT_GW_TCM_GearLevelSwitchSts
    DT_DT_GW_TCM_STATUS_RND
    DT_DT_GW_TCM_Counter_RND
    DT_DT_GW_TCM_CRC_RND
    DT_DT_GW_TCM_SelfCheckSt
    DT_DT_VCU_CRC_B7
    DT_DT_VCU_KeepWorkModeFlag
    DT_DT_VCU_MAI_Active
    DT_DT_VCU_MAI_Available
    DT_DT_VCU_GetCrashStsReq
    DT_DT_VCU_ADASPosTorqueCap_VD
    DT_DT_VCU_ADASPosTorqueCap
    DT_DT_VCU_RollingCounter_B7
    DT_DT_VCU_Vehicle_Warning_IDB7_CCAN
    DT_DT_VCU_VehicleSts_IDB7_CCAN
    DT_DT_VCU_PowerReduceReq
    DT_DT_VCU_ParkingReqToEPB_VD
    DT_DT_VCU_ParkingReqToEPB
    DT_DT_VCU_ACCAvailable
    DT_DT_VCU_ACCActiveSts
    DT_DT_VCU_Active_APS
    DT_DT_VCU_Available_APS
    DT_DT_VCU_ESCActive
    DT_DT_VCU_ESCTorqReqAvailability_Rear
    DT_DT_VCU_AutoHold_ibit
    DT_DT_VCU_VehicleSpeedVD
    DT_DT_VCU_CCSStatus
    DT_DT_VCU_AutoDriveRequest
    DT_DT_VCU_CCSAllow
    DT_DT_VCU_VlcHoldSts
    DT_DT_VCU_HoldReqSts
    DT_DT_VCU_HoldReqStsValid
    DT_DT_VCU_DriverAssistProhibitSts_IDB7_CCAN
    DT_DT_VCU_SpeedLimitedSts
    DT_DT_VCU_SpeedLimitedValue
    DT_DT_VCU_TheoAccePedalPercent
    DT_DT_VCU_RecuBrakeTorqueCap
    DT_DT_VCU_RecuBrakeTorqueAct
    DT_DT_VCU_TheoAccePedalValid
    DT_DT_VCU_HydraTorqTgt
    DT_DT_VCU_RecuBrakeTorqueActDrag
    DT_DT_VCU_ESCTorqReqAvailability_Frnt
    DT_DT_VCU_RecuBrakeTorqueCap_Q
    DT_DT_VCU_RecuBrakeTorqueAct_Q
    DT_DT_VCU_HydraTorqTgt_Q
    DT_DT_VCU_RecuBrakeTorqueActDrag_Q
    DT_DT_VCU_RecuBrakeTorqueTarget_Drag
    DT_DT_VCU_PreventVehSlipSts
    DT_DT_VCU_RecuBrakeTorqueTarget_Drag_Q
    DT_DT_VCU_AllMotWhlTrqFB
    DT_DT_VCU_AllMotWhlTrqFB_VD
    DT_DT_VCU_LSFC_Allow
    DT_DT_VCU_LSFC_Active
    DT_DT_VCU_MGCUWorkMode_C
    DT_DT_VCU_AllRoadSts
    DT_DT_VCU_CmpUTurnAllow
    DT_DT_VCU_CmpUTurnSts
    DT_DT_VCU_AllowCmpUTurnStartFlag
    DT_DT_VCU_CmpUTurnLockWhl
    DT_DT_VCU_CmpUTurnActAngle
    DT_DT_VCU_CmpUTurnActSpinSpd
    DT_DT_VCU_CmpUTurnFltHMI
    DT_DT_VCU_EscapeModeSts
    DT_DT_VCU_MCUSWorkFailMsg
    DT_DT_VCU_EscapeWorkFailMsg
    DT_DT_VCU_REClutchFltMsg
    DT_DT_VCU_BoostMode_Fail_C
    DT_DT_VCU_BoostModeSts_C
    DT_DT_DbgSignal{1..12}_FA
    DT_DT_DbgSignal{1..12}_RA
    DT_DT_ECM_UDS_Res_Byte{0..7}
    DT_DT_VCU_BCM_Authentication_MAC_A{0..15}
    DT_DT_VCU_BCM_Authentication_Challenge_B{0..3}
    DT_DT_TMS_MCUMHeatPwrReq
    DT_DT_TMS_MCUMHeatModEnad
    DT_DT_TMS_VCU_MotSelfHeatEnReq
    DT_DT_TMS_VCU_MotSelfHeatLvlReq
    DT_DT_ECM_SWVersionC
    DT_DT_ECM_SWVersionB
    DT_DT_ECM_SWVersionA
    DT_DT_ECM_Total_fuel_consumed
    DT_DT_IVI_CRC_331
    DT_DT_IVI_RollingCounter_331
    DT_DT_IVI_EPBRequst
    DT_DT_IVI_TerrainMatchMode
    DT_DT_IVI_LPedalModeSW
    DT_DT_IVI_AVHSw_X
    DT_DT_IVI_ESCSw_X
    DT_DT_IVI_HDCSw_X
    DT_DT_IVI_CSTSw_X
    DT_DT_IVI_AutoAllRoad
    DT_DT_IVI_CampingMode_SW
    DT_DT_IVI_BraPedMod
    DT_DT_IVI_SlowspeedSmartCtrl
    DT_DT_IVI_TrailerModeCtrl
    DT_DT_IVI_EscapeMode_SW
    DT_DT_IVI_PowerSavingModeReq
    DT_DT_IVI_SelfAdaptionDriveSW
    DT_DT_IVI_CmpUTurnStartUI
    DT_DT_IVI_CmpUTurnLockWhlUI
    DT_DT_IVI_CmpUTurnTarDirUI
    DT_DT_IVI_CmpUTurnTarAngleUI
    DT_DT_IVI_CmpUTurnReq
    DT_DT_IVI_InventerLimitOdometerkm
    DT_DT_IVI_FuelDetMode
    DT_DT_IVI_EngineIdlingMode
    DT_DT_IVI_CarWashMode
    DT_DT_IVI_CampingModeSW
    DT_DT_IVI_SpeedLimitModeSW
    DT_DT_IVI_FuelupReq
    DT_DT_IVI_FuelChgLevel
    DT_DT_IVI_FuelChgMode
    DT_DT_IVI_InventerLimitOdometerkmVD
    DT_DT_IVI_EMSRepairModeReq
    DT_DT_IVI_ForceChgModeReq
    DT_DT_IVI_ForceChgTargetSOCVD
    DT_DT_IVI_SpeedLimitModeSpeed
    DT_DT_IVI_AWDModeSW
    DT_DT_IVI_ForceChgTargetSOC
    DT_DT_BCM_VCU_Authentication_Sts
    DT_DT_BCM_PTCLossMissErr
    DT_DT_BCM_PTCRollCntErr
    DT_DT_BCM_PTCChksumErr
    DT_DT_BCM_PDUHVIL_STs
    DT_DT_BCM_Cab220VHVIL_STs
    DT_DT_BCM_Cabin220VHVIL_STs
    DT_DT_IBC_CRC_185
    DT_DT_IBC_RollingCounter_185
    DT_DT_IBC_PlungerPressure
    DT_DT_IBC_PlungerPressure_Q
    DT_DT_IBC_SimulatorPressure
    DT_DT_IBC_SimulatorPressure_Q
    DT_DT_IBC_HMI_WarningOn
    DT_DT_IBC_MIL_WarningOn
    DT_DT_IBC_LongitAcceAct
    DT_DT_IBC_LongitAcceActValid
    DT_DT_IBC_brakeFluidWarning
    DT_DT_IBC_SCM_Active
    DT_DT_IBC_SCM_Failed
    DT_DT_IBC_CDPAvailable
    DT_DT_IBC_CDPIntervention
    DT_DT_IBC_AEB_active
    DT_DT_IBC_AEBdecAvailable
    DT_DT_IBC_AVHStatus
    DT_DT_IBC_AVHAvailable
    DT_DT_IBC_HHCActive
    DT_DT_IBC_HHCFailed
    DT_DT_IBC_CDD_Available_APA
    DT_DT_IBC_CDD_Active_APA
    DT_DT_IBC_CDD_Available_ACC
    DT_DT_IBC_CDD_Active_ACC
    DT_DT_IBC_HDCStatus
    DT_DT_IBC_HDCAvailable
    DT_DT_IBC_CSTStatus
    DT_DT_IBC_CSTAvailable
    DT_DT_IBC_VLC_Available_ACC
    DT_DT_IBC_VLC_Active_ACC
    DT_DT_IBC_VLC_Available_APA
    DT_DT_IBC_VLC_Active_APA
    DT_DT_IBC_VehicleHoldStatus
    DT_DT_IBC_DrvrBrkTqAtWhlsReqd
    DT_DT_TMS_RollingCounter_363
    DT_DT_TMS_AC_Command
    DT_DT_TMS_PTCHeatingReq
    DT_DT_TMS_PTCPowerSet
    DT_DT_TMS_OutsideTempVD
    DT_DT_TMS_OutsideTemp_Corrected
    DT_DT_BMS_SOC_Real
    DT_DT_BMS_MODE_t
    DT_DT_BMS_VoltLoDeratLevel_NA
    DT_DT_BMS_VoltHiDeratLevel_NA
    DT_DT_TMS_MCUOutTemp
    DT_DT_TMS_MCUMIntelTemp
    DT_DT_TMS_MCUSIntelTemp
    DT_DT_BCM_VCU_Authentication_Challenge_A{0..3}
    DT_DT_ICU_CRC_DF
    DT_DT_ICU_RollingCounter_DF
    DT_DT_ICU_IMU_ACC_x
    DT_DT_ICU_IMU_ACC_y
    DT_DT_ICU_IMU_ACC_z
    DT_DT_ICU_IMU_ACC_Roll_Rate
    DT_DT_ICU_IMU_ACC_Pitch_Rate
    DT_DT_ICU_IMU_ACC_Yaw_Rate
    DT_DT_ICU_IMU_Calibrated
    DT_DT_ICU_IMU_Valid
    DT_DT_EddyCur_Para_Cos_m
    DT_DT_EddyCur_Stage
    DT_DT_EddyCur_IdenFinish_Flag
    DT_DT_EddyCur_Para_Sin_m
    DT_DT_EddyCur_Write_Flag
    DT_DT_EddyCur_FauPro_IDEL_OTime_Flag
    DT_DT_EddyCur_FauPro_SpdInstab_Flag
    DT_DT_EddyCur_FauPro_IDPara_OVal_Flag
    DT_DT_EddyCur_Para_Cos_k
    DT_DT_EddyCur_Enable
    DT_DT_EddyCur_Para_Sin_k
    DT_DT_EddyCur_IdenFail_Flag
    DT_DT_EddyCur_Para_Cos_Pha
    DT_DT_EddyCur_Para_Sin_Pha
    DT_DT_EddyCur_ReadSuccess_Flag
    DT_DT_OfsIden_ReadSuccess_Flag
    DT_DT_OfsIden_SpdUp_Overtime
    DT_DT_OfsIden_SpdUp_OverSpd
    DT_DT_OfsIden_IdenDiverge
    DT_DT_OfsIden_IdenCntOver
    DT_DT_OfsIden_MtrLock
    DT_DT_OfsIden_OfsRslt
    DT_DT_OfsIden_Sts
    DT_DT_OfsIden_Finish
    DT_DT_OfsIden_OfsWrite_Finish
    DT_DT_OfsIden_DirWrite_Finish
    DT_DT_OfsIden_DirIden_Rslt
    DT_DT_OfsIden_ZeroAlign_OverTime
    DT_DT_OfsIden_ZeroAlign_Fail
    DT_DT_OfsIden_IFStart_Overtime
    DT_DT_OfsIden_IFStart_Fail
    DT_DT_PosDly_Cal_RslvDelayTime
    DT_DT_PosDly_Theta_k_Std
    DT_DT_PosDly_Supplier
    DT_DT_PosDly_FauPro_Ident_OTm_Flag
    DT_DT_PosDly_FauPro_SpdDn_OTm_Flag
    DT_DT_PosDly_RslvOffsetComp
    DT_DT_PosDly_Enable
    DT_DT_PosDly_IdentFail_Flag
    DT_DT_PosDly_IdentFinish_Flag
    DT_DT_PosDly_Write_Flag
    DT_DT_PosDly_FauPro_Chk_DlyTime_OVal
    DT_DT_PosDly_FauPro_Chk_RslvOfst_OVal
    DT_DT_PosDly_FauPro_Check_Divergence
    DT_DT_PosDly_FauPro_SpdUp_OTm_Flag
    DT_DT_PosDly_Stage
    DT_DT_IMParaIdent_ParEstMainStep
    DT_DT_IMParaIdent_Rs
    DT_DT_IMParaIdent_Rr
    DT_DT_IMParaIdent_Ll
    DT_DT_IMParaIdent_Lm
    DT_DT_IMParaIdent_TotalLo
    DT_DT_IMParaIdent_IdentSubStep
    DT_DT_MCUMR_EddyCur_Para_Cos_m
    DT_DT_MCUMR_EddyCur_Stage
    DT_DT_MCUMR_EddyCur_IdenFinish_Flag
    DT_DT_MCUMR_EddyCur_Para_Sin_m
    DT_DT_MCUMR_EddyCur_Write_Flag
    DT_DT_MCUMR_EddyCur_FauPro_IDEL_OTime_Flag
    DT_DT_MCUMR_EddyCur_FauPro_SpdInstab_Flag
    DT_DT_MCUMR_EddyCur_FauPro_IDPara_OVal_Flag
    DT_DT_MCUMR_EddyCur_Para_Cos_k
    DT_DT_MCUMR_EddyCur_Enable
    DT_DT_MCUMR_EddyCur_Para_Sin_k
    DT_DT_MCUMR_EddyCur_IdenFail_Flag
    DT_DT_MCUMR_EddyCur_Para_Cos_Pha
    DT_DT_MCUMR_EddyCur_Para_Sin_Pha
    DT_DT_MCUMR_EddyCur_ReadSuccess_Flag
    DT_DT_MCUMR_OfsIden_ReadSuccess_Flag
    DT_DT_MCUMR_OfsIden_SpdUp_Overtime
    DT_DT_MCUMR_OfsIden_SpdUp_OverSpd
    DT_DT_MCUMR_OfsIden_IdenDiverge
    DT_DT_MCUMR_OfsIden_IdenCntOver
    DT_DT_MCUMR_OfsIden_MtrLock
    DT_DT_MCUMR_OfsIden_OfsRslt
    DT_DT_MCUMR_OfsIden_Sts
    DT_DT_MCUMR_OfsIden_Finish
    DT_DT_MCUMR_OfsIden_OfsWrite_Finish
    DT_DT_MCUMR_OfsIden_DirWrite_Finish
    DT_DT_MCUMR_OfsIden_DirIden_Rslt
    DT_DT_MCUMR_OfsIden_ZeroAlign_OverTime
    DT_DT_MCUMR_OfsIden_ZeroAlign_Fail
    DT_DT_MCUMR_OfsIden_IFStart_Overtime
    DT_DT_MCUMR_OfsIden_IFStart_Fail
    DT_DT_MCUM_StatorTemp_1
    DT_DT_MCUM_L2TqAct
    DT_DT_MCUM_EOPSw
    DT_DT_MCUM_StatorTemp_2
    DT_DT_MCUM_IGBTTemp_U
    DT_DT_MCUM_IGBTTemp_V
    DT_DT_MCUM_IGBTTemp_W
    DT_DT_MCUM_PCBTemp
    DT_DT_MCUM_Power_12V
    DT_DT_MCUM_Power_15V
    DT_DT_MCUM_Offset_IU
    DT_DT_MCUM_Offset_IV
    DT_DT_MCUM_Offset_IW
    DT_DT_MCUM_MainSt_State
    DT_DT_MCUM_Derate_Reason
    DT_DT_MCUM_PWM_Freq_kHz
    DT_DT_MCUM_PWMEn_State
    DT_DT_MCUM_DrvPwrEn_Out_State
    DT_DT_MCUM_SBC_SelfCheckFault
    DT_DT_MCUM_SBC_TempOverFault
    DT_DT_MCUM_SBC_SPIFault
    DT_DT_MCUM_SBC_InsideVotageFault
    DT_DT_MCUM_SBC_OutPutVotageFault
    DT_DT_MCUM_SBC_FeedDogFault
    DT_DT_MCUM_NVM_RslvrZeroRFault
    DT_DT_MCUM_Rotor_Position
    DT_DT_MCUM_PosTransduserFaultCode
    DT_DT_MCUM_NVM_RslvrDirRFault
    DT_DT_MCUM_NVM_RslvrDelayRFault
    DT_DT_MCUM_NVM_RslvrParamRFault
    DT_DT_MCUM_NVM_HallGainRFault
    DT_DT_MCUM_NVM_HallDelayRFault
    DT_DT_MCUM_NVM_IGBTTypeRFault
    DT_DT_MCUM_NVM_MotorTypeRFault
    DT_DT_MCUM_NVM_VehicleTypeRFault
    DT_DT_MCUM_ASC_EntryCount
    DT_DT_MCUM_Spd_Turn
    DT_DT_MCUM_LUT_Spd_Max
    DT_DT_MCUM_EOP_Speed
    DT_DT_MCUM_EOP_IqFb
    DT_DT_MCUM_EOP_IqRef
    DT_DT_MCUM_EOP_DCVolt
    DT_DT_MCUM_EOP_DCCurr
    DT_DT_MCUM_EOP_Temp
    DT_DT_MCUM_EOP_State
    DT_DT_MCUM_EOP_FaultCode
    DT_DT_MCUM_HWFault_RstCnt
    DT_DT_MCUM_HWFoB_RstCnt
    DT_DT_MCUM_HWFoT_RstCnt
    DT_DT_MCUM_HWDrvUV_RstCnt
    DT_DT_MCUM_HWRdc_RstCnt
    DT_DT_MCUM_HWOC_RstCnt
    DT_DT_MCUM_HWOV_RstCnt
    DT_DT_MCUM_L2agRtrElecDiff
    DT_DT_MCUM_500usOverTime_Cnt
    DT_DT_MCUM_5msOverTime_Cnt
    DT_DT_MCUM_12VHop_Cnt
    DT_DT_MCUM_12V_Max
    DT_DT_MCUM_12V_Min
    DT_DT_MCUM_NVMFail_Cnt
    DT_DT_MCUM_EOL_CANCommReq
    DT_DT_MCUM_ResetReason
    DT_DT_MCUM_CpldRest_TimeOut_flag
    DT_DT_MCUM_DrvPCBCurr
    DT_DT_MCUM_EOL_StateMachine
    DT_DT_MCUM_CpldRest_ASC_Flag
    DT_DT_MCUM_LimSpdTorFlag
    DT_DT_MCUM_PWM_Err_Count
    DT_DT_MCUM_RDC_Reset_Count
    DT_DT_MCUM_ASC_Stop_Flag
    DT_DT_MCUM_ASC_Soft_Exiting_Flag
    DT_DT_MCUM_Vbus_ServeLowChkEn
    DT_DT_MCUM_EOP_BlockErr_IsLim_Flag
    DT_DT_MCUM_MotSelfHeat_EnSts
    DT_DT_MCUM_MotBlockHeat_LvlFb
    DT_DT_MCUM_MotRotaryHeat_LvlFb
    DT_DT_MCUM_MotSelfHeat_DropLvlFb
    DT_DT_MCUM_MotSelfHeat_DropLvlRsn
    DT_DT_MCUM_MotBlockHeat_CurAngle
    DT_DT_MCUM_MotBlockHeat_CurMag
    DT_DT_MCUM_FaultDataRec_State
    DT_DT_MCUM_UserDefine_Byte{1..4}
    DT_DT_MCUM_UserDefine_Word{1..3}
    DT_DT_ECM_EngineWorktime
    DT_DT_GTC_TestSts
    DT_DT_GTC_ThetaPos
    DT_DT_GTC_ThetaNeg
    DT_DT_GTC_ThetaDelt
    DT_DT_GTC_TestRslt
    DT_DT_MCUMR_GTC_TestSts
    DT_DT_MCUMR_GTC_ThetaPos
    DT_DT_MCUMR_GTC_ThetaNeg
    DT_DT_MCUMR_GTC_ThetaDelt
    DT_DT_MCUMR_GTC_TestRslt
    DT_DT_MCUM_CRC_CA
    DT_DT_MCUM_RollingCounter_CA
    DT_DT_MCUM_WarningLevel
    DT_DT_MCUM_SelfCheckSts
    DT_DT_MCUM_DrvMotorWorkSts
    DT_DT_MCUM_PowerReduceSts
    DT_DT_MCUM_SystemError
    DT_DT_MCUM_DrvMotorRPM
    DT_DT_MCUM_ActualTorqueFB
    DT_DT_MCUM_HWRdcFault
    DT_DT_MCUM_LVSystemError
    DT_DT_MCUM_HighVoltPowerOffReq
    DT_DT_MCUM_HVILSts
    DT_DT_MCUM_DragSts
    DT_DT_MCUM_CtrlMode
    DT_DT_MCUM_MotorTempAlarm
    DT_DT_MCUM_HVSystemError
    DT_DT_MCUM_MILlampReq
    DT_DT_MCUM_SeriousWarning_Level
    DT_DT_MCUM_DrvMotorRPMVD
    DT_DT_MCUM_ActualTorqueFBVD
    DT_DT_MCUM_CtrlModeVD
    DT_DT_MCUM_MaxTorqueAllow
    DT_DT_MCUM_MaxSpeedAllow
    DT_DT_MCUM_WaterPumpLevlReq
    DT_DT_MCUM_ActiveReleaseSts
    DT_DT_MCUM_DCChargRelaySts
    DT_DT_MCUM_Fault_DCChargRelay
    DT_DT_MCUM_MinTorqueAllow
    DT_DT_MCUM_MainWireVolt
    DT_DT_MCUM_MotorTemp
    DT_DT_MCUM_IGBTTemp
    DT_DT_MCUM_InletTemp
    DT_DT_MCUM_MainWireCurr
    DT_DT_MCUM_TMS_MotSelfHeatEnSts
    DT_DT_MCUM_TMS_MotSelfHeatLvlFb
    DT_DT_MCUM_HeatPwrAllwd
    DT_DT_MCUM_HeatFdBck
    DT_DT_MCUM_RPowerReduceSts
    DT_DT_MCUM_HeatPwrAct
    DT_DT_MCUM_HeatPwrMax
    DT_DT_MCUM_HeatPwrAval
    DT_DT_MCUM_RCtrlMode
    DT_DT_MCUM_RWarningLevel
    DT_DT_MCUM_RSelfCheckSts
    DT_DT_MCUM_RDrvMotorWorkSts
    DT_DT_MCUM_RCtrlModeVD
    DT_DT_MCUM_RHWRdcFault
    DT_DT_MCUM_RDrvMotorRPMVD
    DT_DT_MCUM_RActualTorqueFBVD
    DT_DT_MCUM_RDrvMotorRPM
    DT_DT_MCUM_RActualTorqueFB
    DT_DT_IBC_CRC_182
    DT_DT_IBC_RollingCounter_182
    DT_DT_IBC_VehicleSpeed
    DT_DT_IBC_VehicleSpeedVD
    DT_DT_IBC_ABSActive
    DT_DT_IBC_ABSFailed
    DT_DT_IBC_TCSActive
    DT_DT_IBC_TCSFailed
    DT_DT_IBC_ESCFunctionStatus
    DT_DT_IBC_BrakeForce
    DT_DT_IBC_Vehiclestandstill
    DT_DT_IBC_EBDFailed
    DT_DT_IBC_EBDActive
    DT_DT_IBC_VDCActive
    DT_DT_IBC_VDCFailed
    DT_DT_IBC_EDCActive
    DT_DT_IBC_EDCFailed
    DT_DT_IBC_SystemInitializeStatus
    DT_DT_IBC_BTCSActive
    DT_DT_IBC_ETCSActive
    DT_DT_IBC_ARPActive
    DT_DT_IBC_VCU_DrumMode
    DT_DT_IBC_EscapeModeSts
    DT_DT_IBC_TSAActive
    DT_DT_IBC_TSAStatus
    DT_DT_MCUM_FaultData{0..14}
    DT_DT_MCUM_R_FaultData{0..14}
    DT_DT_ICU_CRC_24D
    DT_DT_ICU_SpeedConversionCoefficient
    DT_DT_ICU_RollingCounter_24D
    DT_DT_ICU_CCSFunctionStatus
    DT_DT_ICU_CruiseVehicleSpeedCtl
    DT_DT_ICU_VehicleScreenSpeed
    DT_DT_ICU_VehicleSpeedUnit
    DT_DT_ICU_ACCFunctionStatus
    DT_DT_ICU_LCCFunctionStatus
    DT_DT_IVI_LPedalMode
    DT_DT_ICU_TotalOilmeterkm
    DT_DT_ICU_CLTCoilMileage
    DT_DT_ICU_WLTC_oilMileage
    DT_DT_ICU_CLTC_ElectticityMileage
    DT_DT_ICU_WLTC_ElectticityMileage
    DT_DT_ICU_Switch_CLTCOrWLTC
    DT_DT_ICU_FuelPercent
    DT_DT_ACU_CRC_233
    DT_DT_ACU_RollingCounter_233
    DT_DT_ACU_LateralAcce
    DT_DT_ACU_LongitAcce
    DT_DT_ACU_LateralAcceValid
    DT_DT_ACU_LongitAcceValid
    DT_DT_ACU_SensorCalSt
    DT_DT_ACU_YawRate
    DT_DT_ACU_YawRateValid
    DT_DT_MotClb_UdFb
    DT_DT_MotClb_UqFb
    DT_DT_MotClb_IdSet
    DT_DT_MotClb_IqSet
    DT_DT_MotClb_IsCMD_Fb
    DT_DT_MotClb_ThetaCMD_Fb
    DT_DT_MotClb_Id_Fb
    DT_DT_MotClb_Iq_Fb
    DT_DT_MotClb_Spd_rpm_Flt
    DT_DT_MotClb_ThtSetReal
    DT_DT_MotClb_Power_Inverter
    DT_DT_MotClb_Volt_DC
    DT_DT_MotClb_UsOutFlt
    DT_DT_MotClb_CoolWater_Temp
    DT_DT_MotClb_Motor_Temp1_Flt
    DT_DT_MotClb_IGBT_Temp1
    DT_DT_MotClb_ErrLevel
    DT_DT_MCUMR_MotClb_UdFb
    DT_DT_MCUMR_MotClb_UqFb
    DT_DT_MCUMR_MotClb_IdSet
    DT_DT_MCUMR_MotClb_IqSet
    DT_DT_MCUMR_MotClb_IsCMD_Fb
    DT_DT_MCUMR_MotClb_ThetaCMD_Fb
    DT_DT_MCUMR_MotClb_Id_Fb
    DT_DT_MCUMR_MotClb_Iq_Fb
    DT_DT_MCUMR_MotClb_Spd_rpm_Flt
    DT_DT_MCUMR_MotClb_ThtSetReal
    DT_DT_MCUMR_MotClb_Power_Inverter
    DT_DT_MCUMR_MotClb_Volt_DC
    DT_DT_MCUMR_MotClb_UsOutFlt
    DT_DT_MCUMR_MotClb_CoolWater_Temp
    DT_DT_MCUMR_MotClb_Motor_Temp1_Flt
    DT_DT_MCUMR_MotClb_IGBT_Temp1
    DT_DT_MCUMR_MotClb_ErrLevel
    DT_DT_BMS_CRC_1A1
    DT_DT_BMS_RollingCounter_1A1
    DT_DT_BMS_Warning_Level
    DT_DT_BMS_SelfCheck
    DT_DT_BMS_BattChargerSts
    DT_DT_BMS_RHighVolSts
    DT_DT_BMS_RPreChargeRelayFB
    DT_DT_BMS_RPositiveRelayFB
    DT_DT_BMS_RNegativeRelayFB
    DT_DT_BMS_RPositiveRelay_F
    DT_DT_BMS_RNegativeRelay_F
    DT_DT_BMS_RPreChargeFinishSts
    DT_DT_BMS_MCUMHVILSts
    DT_DT_BMS_ACPTCHVILSts
    DT_DT_BMS_PTCHVILSts
    DT_DT_BMS_CCMHVILSts
    DT_DT_BMS_CDUHVILSts
    DT_DT_BMS_DCChgHVILSts
    DT_DT_BMS_MCUSHVILSts
    DT_DT_BMS_HVOffSts
    DT_DT_BMS_SeriousWarning_Level
    DT_DT_BMS_DCChgRelayCloseReq
    DT_DT_BMS_DCChgRelayFB
    DT_DT_BMS_ChgStopReason
    DT_DT_BMS_GCUHVILSts
    DT_DT_BMS_MILlampReq
    DT_DT_BMS_IsoRessistanceSts
    DT_DT_BMS_Integrity_Check
    DT_DT_BMS_BattVolt
    DT_DT_BMS_BattCurr
    DT_DT_BMS_BatDyn_Dchgpwr
    DT_DT_BMS_BatDyn_Chgpwr
    DT_DT_BMS_Precharge_CoolingSts
    DT_DT_IBC_CRC_B1
    DT_DT_IBC_RollingCounter_B1
    DT_DT_IBC_EngTorqDec_Main
    DT_DT_IBC_EngTorqDecActive_Main
    DT_DT_IBC_EngTorqInc_Main
    DT_DT_IBC_EngTorqIncActive_Main
    DT_DT_IBC_EngTorqDec_Sub
    DT_DT_IBC_EngTorqDecActive_Sub
    DT_DT_IBC_EngTorqInc_Sub
    DT_DT_IBC_EngTorqIncActive_Sub
    DT_DT_IBC_EngTorqDec_MainR
    DT_DT_IBC_EngTorqDecActive_MainR
    DT_DT_IBC_EngTorqInc_MainR
    DT_DT_IBC_EngTorqIncActive_MainR
    DT_DT_ADDC_CRC_83
    DT_DT_ADDC_ACC_AVHReq
    DT_DT_ADDC_ACC_HoldSts
    DT_DT_ADDC_ACCTargetTrq
    DT_DT_ADDC_ACCTargetTrqVD
    DT_DT_ADDC_ACCTargetTrqBrkVD
    DT_DT_ADDC_ACCTargetTrqBrk
    DT_DT_ADDC_MAIWarnTrqCtrlFlg
    DT_DT_ADDC_RollingCounter_83
    DT_DT_ADDC_ACC_FunType
    DT_DT_ADDC_ACCMode
    DT_DT_ADDC_Driveoff_Request
    DT_DT_ADDC_DecToStop
    DT_DT_ADDC_ACCAvailable
    DT_DT_ADDC_ACCTargetAcc
    DT_DT_ADDC_ACCTargetAccVD
    DT_DT_ADDC_ACC_RecordingPulse
    DT_DT_ADDC_VehicleSpeedCtlVD
    DT_DT_ADDC_VehicleSpeedCtl
    DT_DT_ADDC_ACC_EPBReq
    DT_DT_ADDC_ACC_VehicleDirectCtl
    DT_DT_ADDC_ACC_VehicleDirectCtlVD
    DT_DT_ADDC_AEBTargetDec
    DT_DT_ADDC_AEBDecCtrl
    DT_DT_ADDC_AEBMode
    DT_DT_ADDC_AEBAvailable
    DT_DT_ADDC_ACC_VLCCtlReq
    DT_DT_ADDC_ACC_OvrdSts
    DT_DT_ADDC_RCTB_DecReq
    DT_DT_ADDC_RAEB_DecReq
    DT_DT_ADDC_MEB_DecReq
    DT_DT_VCU_CRC_13B
    DT_DT_VCU_RollingCounter_13B
    DT_DT_VCU_Vehicle_Warning
    DT_DT_VCU_VehicleSts
    DT_DT_VCU_GearLevelPosSts
    DT_DT_VCU_GearLeverValid
    DT_DT_VCU_AccPedalValid
    DT_DT_VCU_ThrottlePosition
    DT_DT_VCU_BMSMainRelayR_Cmd
    DT_DT_VCU_BMSMainRelayF_Cmd
    DT_DT_VCU_BMSEmergencyCmd
    DT_DT_VCU_MCUMActiveReleaseCmd
    DT_DT_VCU_MCUSActiveReleaseCmd
    DT_DT_VCU_AlwACChargeInventerSts
    DT_DT_VCU_AlwDCChargeSts
    DT_DT_VCU_ChargePauseReq
    DT_DT_VCU_SuppressJitterMCUSRequest
    DT_DT_VCU_DCDCEnableCmd
    DT_DT_VCU_ACOffReq
    DT_DT_VCU_VehicleDirect
    DT_DT_VCU_BrakeSysFault
    DT_DT_VCU_SuppressJitterMCUMRequest
    DT_DT_VCU_MDrvControlMode
    DT_DT_VCU_BrakePedalValue
    DT_DT_VCU_MCUMMaxDischargePower
    DT_DT_VCU_MCUMMaxChargePower
    DT_DT_VCU_MDrvRequestTorque
    DT_DT_VCU_MDrvRequesSpeed
    DT_DT_VCU_SDrvRequestTorque
    DT_DT_VCU_SDrvRequesSpeed
    DT_DT_VCU_SVehicleSts
    DT_DT_VCU_VehicleHighVoltModeF
    DT_DT_VCU_SDrvControlMode
    DT_DT_VCU_ON2BRelayReq
    DT_DT_VCU_VehPreHVPwrOffCmd
    DT_DT_VCU_FuelTankLockReq
    DT_DT_VCU_VehicleDirectS
    DT_DT_VCU_VehicleDirectS_VD
    DT_DT_VCU_ACPwrLimited
    DT_DT_VCU_MCUSMaxDischargePower
    DT_DT_VCU_VehicleDirectVD
    DT_DT_VCU_MDrvControlModeVD
    DT_DT_VCU_MDrvRequestTorqueVD
    DT_DT_VCU_MDrvRequesSpeedVD
    DT_DT_VCU_SDrvRequestTorqueVD
    DT_DT_VCU_SDrvRequesSpeedVD
    DT_DT_VCU_SDrvControlModeVD
    DT_DT_VCU_MCUSMaxChargePower
    DT_DT_VCU_VehicleHighVoltMode
    DT_DT_VCU_PDUHVIL_Sts
    DT_DT_VCU_PDU220VRelay_Req
    DT_DT_VCU_Cab220VRelay_Req
    DT_DT_VCU_Cabin220VRelay_Req
    DT_DT_VCU_Alw_Cab220VInverter_Sts
    DT_DT_VCU_Alw_Cabin220VInverter_Sts
    DT_DT_VCU_MCUMDampgLmtFactor
    DT_DT_VCU_MCUSDampgLmtFactor
    DT_DT_VCU_BCM_Authentication_Sts
    DT_DT_VCU_AuthenticationKey_WSts
    DT_DT_VCU_BrakePedalSts_P
    DT_DT_VCU_BrakePedalStsValid_P
    DT_DT_VCU_BoostMode_Fail
    DT_DT_VCU_BoostModeSts
    DT_DT_VCU_MCUSMaxPosDampgTrq
    DT_DT_VCU_MCUSMaxNegDampgTrq
    DT_DT_VCU_MCUMMaxPosDampgTrq
    DT_DT_VCU_MCUMMaxNegDampgTrq
    DT_DT_BMS_InverterPower
    DT_DT_BMS_MaxChargeVolt
    DT_DT_BMS_MaxChargeCurr
    DT_DT_BMS_OBCWorkModeCtrl
    DT_DT_BMS_MaxPower
    DT_DT_BMS_ChargerACInput
    DT_DT_BMS_ChargerDCInput
    DT_DT_BMS_ChargeRequest
    DT_DT_BMS_InverterRequest
    DT_DT_BMS_ChargeQuantity
    DT_DT_BMS_BattMaxTemp
    DT_DT_BMS_BattMinTemp
    DT_DT_BMS_BattIntakeTemp
    DT_DT_BMS_BattIOutletTemp
    DT_DT_BMS_BattSOC_Display
    DT_DT_BMS_Req_Cab220VInverter_Sts
    DT_DT_BMS_Req_Cabin220VInverter_Sts
    DT_DT_BMS_RemainEnergy
    DT_DT_BMS_StateOfEngeryMax
    DT_DT_BMS_ThermalManageRequest
    DT_DT_BMS_PreHeatingState
    DT_DT_LMC_CRC_FD
    DT_DT_LMC_RollingCounter_FD
    DT_DT_LMC_SysSt
    DT_DT_LMC_HSPC_ActiveSt
    DT_DT_LMC_FTSC_ActiveSt
    DT_DT_LMC_SDRM_ActiveSt
    DT_DT_LMC_NSPC_ActiveSt
    DT_DT_LMC_EAF_ActiveSt
    DT_DT_LMC_SelfCheckSt
    DT_DT_LMC_WBDC_ActiveSt
    DT_DT_MCUM_UDS_SW{1..10}
    DT_DT_MCUM_UDS_HW{1..10}
    DT_DT_MCUM_UDS_Boot{1..10}
    DT_DT_MCUM_UDS_ProductModel{1..16}
    DT_DT_MCUM_UDS_Supplier{1..6}
    DT_DT_VCU_BrkPedOpen
    DT_DT_VCU_BrkPedClose
    DT_DT_VCU_ColumnShiftP
    DT_DT_VCU_VehiCrashSts
    DT_DT_VCU_SleepSatisfiedSts
    DT_DT_VCU_VehiHvCmd
    DT_DT_VCU_GearQuitAps
    DT_DT_VCU_REOverChgPwrFlag
    DT_DT_VCU_VehiAccnFilt
    DT_DT_VCU_HvOffSts
    DT_DT_VCU_ElecPwrBalanceReq
    DT_DT_VCU_CDU_RecvTr
    DT_DT_VCU_BMS_RecvTr
    DT_DT_VCU_IVI_RecvTr
    DT_DT_VCU_WheelMaxDrvTrq
    DT_DT_VCU_WheelMaxRecTrq
    DT_DT_VCU_GCU_RecvTr
    DT_DT_VCU_TCM_RecvTr
    DT_DT_VCU_PTC_RecvTr
    DT_DT_VCU_LossFctorFlgFL
    DT_DT_VCU_LowBattVolt
    DT_DT_VCU_HighPerforDisable
    DT_DT_VCU_AccPedHSigVolt
    DT_DT_VCU_LossFctorFlgFR
    DT_DT_VCU_AccPedLSigVolt
    DT_DT_VCU_LossFctorFlgRL
    DT_DT_VCU_AccPedHPwrVolt
    DT_DT_VCU_LossFctorFlgRR
    DT_DT_VCU_AccPedLPwrVolt
    DT_DT_VCU_PreReqChgPwr
    DT_DT_VCU_VehPwrChageLimit
    DT_DT_VCU_FastPwrRequest
    DT_DT_VCU_On2KL15_Volt
    DT_DT_VCU_ClutchWrkModDebug
    DT_DT_VCU_HighPerforSwtFlg
    DT_DT_VCU_VehiPowrConsumption
    DT_DT_VCU_MDrvFilterTrqRange
    DT_DT_VCU_WheelPwrOvrLimitflgRE
    DT_DT_VCU_MRDrvControlMode
    DT_DT_VCU_MRDrvControlModeVD
    DT_DT_VCU_VehicleDirectMR
    DT_DT_VCU_VehicleDirectMRVD
    DT_DT_VCU_MRDrvRequestTorque
    DT_DT_VCU_MRDrvRequesSpeed
    DT_DT_VCU_MCUMRMaxDischargePower
    DT_DT_VCU_MCUMRMaxPosDampgTrq
    DT_DT_VCU_MRDrvRequestTorqueVD
    DT_DT_VCU_MCUMRMaxChargePower
    DT_DT_VCU_MCUMRMaxNegDampgTrq
    DT_DT_VCU_MRDrvRequesSpeedVD
    DT_DT_VCU_MCUMRDampgLmtFactor
    DT_DT_VCU_SuppressJitterMCUMRRequest
    DT_DT_EOL_VCU_BrkPedOpen
    DT_DT_EOL_VCU_BrkPedClose
    DT_DT_EOL_VCU_ColumnShiftP
    DT_DT_EOL_VCU_VehiCrashSts
    DT_DT_EOL_VCU_SleepSatisfiedSts
    DT_DT_EOL_VCU_VehiHvCmd
    DT_DT_EOL_VCU_GearQuitAps
    DT_DT_EOL_VCU_REOverChgPwrFlag
    DT_DT_EOL_VCU_VehiAccnFilt
    DT_DT_EOL_VCU_HvOffSts
    DT_DT_EOL_VCU_ElecPwrBalanceReq
    DT_DT_EOL_VCU_CDU_RecvTr
    DT_DT_EOL_VCU_BMS_RecvTr
    DT_DT_EOL_VCU_IVI_RecvTr
    DT_DT_EOL_VCU_WheelMaxDrvTrq
    DT_DT_EOL_VCU_WheelMaxRecTrq
    DT_DT_EOL_VCU_GCU_RecvTr
    DT_DT_EOL_VCU_TCM_RecvTr
    DT_DT_EOL_VCU_PTC_RecvTr
    DT_DT_EOL_VCU_LossFctorFlgFL
    DT_DT_EOL_VCU_LowBattVolt
    DT_DT_EOL_VCU_HighPerforDisable
    DT_DT_EOL_VCU_AccPedHSigVolt
    DT_DT_EOL_VCU_LossFctorFlgFR
    DT_DT_EOL_VCU_AccPedLSigVolt
    DT_DT_EOL_VCU_LossFctorFlgRL
    DT_DT_EOL_VCU_AccPedHPwrVolt
    DT_DT_EOL_VCU_LossFctorFlgRR
    DT_DT_EOL_VCU_AccPedLPwrVolt
    DT_DT_EOL_VCU_PreReqChgPwr
    DT_DT_EOL_VCU_VehPwrChageLimit
    DT_DT_EOL_VCU_FastPwrRequest
    DT_DT_EOL_VCU_On2KL15_Volt
    DT_DT_EOL_VCU_ClutchWrkModDebug
    DT_DT_EOL_VCU_HighPerforSwtFlg
    DT_DT_EOL_VCU_VehiPowrConsumption
    DT_DT_EOL_VCU_MDrvFilterTrqRange
    DT_DT_EOL_VCU_WheelPwrOvrLimitflgRE
    DT_DT_EOL_VCU_MRDrvControlMode
    DT_DT_EOL_VCU_MRDrvControlModeVD
    DT_DT_EOL_VCU_VehicleDirectMR
    DT_DT_EOL_VCU_VehicleDirectMRVD
    DT_DT_EOL_VCU_MRDrvRequestTorque
    DT_DT_EOL_VCU_MRDrvRequesSpeed
    DT_DT_EOL_VCU_MCUMRMaxDischargePower
    DT_DT_EOL_VCU_MCUMRMaxPosDampgTrq
    DT_DT_EOL_VCU_MRDrvRequestTorqueVD
    DT_DT_EOL_VCU_MCUMRMaxChargePower
    DT_DT_EOL_VCU_MCUMRMaxNegDampgTrq
    DT_DT_EOL_VCU_MRDrvRequesSpeedVD
    DT_DT_EOL_VCU_MCUMRDampgLmtFactor
    DT_DT_EOL_VCU_SuppressJitterMCUMRRequest
    DT_DT_GCU_SWVersionC
    DT_DT_GCU_SWVersionB
    DT_DT_GCU_SWVersionA
    DT_DT_VCU_CRC_B6
    DT_DT_VCU_TVTest2
    DT_DT_VCU_VPE_Test1
    DT_DT_VCU_VPE_Test2
    DT_DT_VCU_TVTest1
    DT_DT_VCU_RollingCounter_B6
    DT_DT_VCU_MDrvRequestTorque_IDB6_CCAN
    DT_DT_VCU_MDriverRequireTorque
    DT_DT_VCU_SDrvRequestTorque_IDB6_CCAN
    DT_DT_VCU_SDriverRequireTorque
    DT_DT_VCU_ThrottlePosition_IDB6_CCAN
    DT_DT_VCU_AccPedalValid_IDB6_CCAN
    DT_DT_VCU_BrakeSysFault_IDB6_CCAN
    DT_DT_VCU_BrakeLightReq
    DT_DT_VCU_BrakePedalSts
    DT_DT_VCU_BrakePedalStsValid
    DT_DT_VCU_GearLevelPosSts_IDB6_CCAN
    DT_DT_VCU_GearLeverValid_IDB6_CCAN
    DT_DT_VCU_BrakeFirstSts
    DT_DT_VCU_DeliveryModeSts_IDB6_CCAN
    DT_DT_VCU_MRDrvRequestTorque_IDB6_CCAN
    DT_DT_VCU_MRDriverRequireTorque
    DT_DT_BCM_CRC_291
    DT_DT_BCM_ShutdownMode
    DT_DT_BCM_NM_PNC_ON_1ADr_Sts
    DT_DT_BCM_RollingCounter_291
    DT_DT_BCM_KeyPosition_ON2A
    DT_DT_BCM_CcmHvilSts_ID291
    DT_DT_BCM_DriverDoorSts
    DT_DT_BCM_FLDoorSts
    DT_DT_BCM_FRDoorSts
    DT_DT_BCM_RLDoorSts
    DT_DT_BCM_RRDoorSts
    DT_DT_BCM_BackDoorSts
    DT_DT_BCM_ON2BRelaySts
    DT_DT_BCM_ON2CRelaySts
    DT_DT_BCM_ON2InitiativeSts
    DT_DT_BCM_VehicleRepairMode
    DT_DT_BCM_VehlockCtrl
    DT_DT_BCM_VehLockSts
    DT_DT_BCM_FuelTankLockReq
    DT_DT_BCM_ACChgLockCtrl
    DT_DT_BCM_ChargeLockCtrl
    DT_DT_BCM_DCChrgPwr_Sts_ID291
    DT_DT_BCM_ACChrgPwr_Sts_ID291
    DT_DT_BCM_DCChrgPwr_Volt_ID291
    DT_DT_BCM_ACChrgPwr_Volt_ID291
    DT_DT_BCM_KeyPosition_ON2B
    DT_DT_BCM_NM_PNC_ON_3Ch_Sts
    DT_DT_BCM_HighVoltageReq
    DT_DT_LMC_CRC_25A
    DT_DT_LMC_ECAS_DriveModeFb
    DT_DT_LMC_CDC_DriveModeFb
    DT_DT_LMC_RollingCounter_25A
    DT_DT_LMC_LSFCActiveSt
    DT_DT_LMC_EngTorqDec_Main_R
    DT_DT_LMC_EngTorqDecActive_Main_R
    DT_DT_LMC_EngTorqInc_Main_R
    DT_DT_LMC_EngTorqIncActive_Main_R
    DT_DT_ACU_CRC_2A3
    DT_DT_ACU_Trigger
    DT_DT_ACU_RollingCounter_2A3
    DT_DT_ACU_TotalCrashOutputSts
    DT_DT_ACU_SelfCheckSt
    DT_DT_ACU_FLSeatBeltRSt
    DT_DT_ACU_FRSeatBeltRSt
    DT_DT_IVI_DeliveryModeReq
    DT_DT_IVI_ShowCarModeReq
    DT_DT_VCU_CheckSum_BB
    DT_DT_VCU_WorkModeReq_PHEV
    DT_DT_VCU_WorkMode_PHEV
    DT_DT_VCU_HEVAllow_PHEV
    DT_DT_VCU_REAllow_PHEV
    DT_DT_VCU_EVDualAllow_PHEV
    DT_DT_VCU_EVSingleAllow_PHEV
    DT_DT_VCU_Clutch_2_RequesSpeed
    DT_DT_VCU_Clutch_1_RequesSpeed
    DT_DT_VCU_Clutch2Position
    DT_DT_VCU_Clutch1Position
    DT_DT_VCU_RollingCounter_BB
    DT_DT_VCU_EngPreStartFlg
    DT_DT_VCU_FuelChgModeMsg
    DT_DT_VCU_FuelChgModeSts
    DT_DT_VCU_RoughRoadDetectionFlag
    DT_DT_VCU_Clutch_2_RequesSpeedValid
    DT_DT_VCU_Clutch_1_RequesSpeedValid
    DT_DT_VCU_GCURequestTorque
    DT_DT_VCU_PowerReducetSts
    DT_DT_VCU_GCUAassistFB
    DT_DT_VCU_GCUActiveReleaseCmd
    DT_DT_VCU_PowerOverSts
    DT_DT_VCU_GCURequesSpeed
    DT_DT_VCU_GCUControlMode
    DT_DT_VCU_MotChargePower
    DT_DT_VCU_APS1Position
    DT_DT_VCU_EngineStartReq
    DT_DT_VCU_EngineFuelInhibitReq
    DT_DT_VCU_EngineOffRequest
    DT_DT_VCU_STorqueReqValid
    DT_DT_VCU_STorqueReq
    DT_DT_VCU_FTorqueSwFb
    DT_DT_VCU_FVVOpenReq
    DT_DT_VCU_WarmUpCycleIndicator
    DT_DT_VCU_EngineResetSts
    DT_DT_VCU_EngineSts
    DT_DT_VCU_FTorqueReq
    DT_DT_VCU_FTorqueReqValid
    DT_DT_VCU_EngineIdleReq
    DT_DT_VCU_REsystemSts
    DT_DT_VCU_REsystemFaultSts
    DT_DT_VCU_APS2Position
    DT_DT_VCU_EngineRunAllowFlg
    DT_DT_VCU_EngineIdleSpeed
    DT_DT_VCU_EngineFuleCutoffReq
    DT_DT_VCU_MCUSClutchPosition
    DT_DT_VCU_MGCUWorkMode
    DT_DT_VCU_REChgTarget
    DT_DT_VCU_MotStartStopPowerUP
    DT_DT_VCU_MotStartStopPowerLOW
    DT_DT_VCU_GCURequesSpeed_MGCU
    DT_DT_VCU_DynamicChgPwr
    DT_DT_VCU_ForceChgPwr
    DT_DT_VCU_REStartType
    DT_DT_VCU_Pending_DTC
    DT_DT_VCU_Comfirmed_DTC
    DT_DT_VCU_Permanent_DTC
    DT_DT_VCU_MilReq_DTC
    DT_DT_MCUM_NMControlRMR_Sts
    DT_DT_MCUM_WakeUpReason
    DT_DT_MCUM_NMControlRMR_Sts_P
    DT_DT_MCUM_WakeUpReason_P
    DT_DT_ECM_ClearingSparkcarbonedRequest
    DT_DT_TMS_RAPTC_ModOprtgStsFrt
    DT_DT_TMS_RAPTC_ModOpEnblCmd
    DT_DT_TMS_RAPTC_MsrdPwrFrt
    DT_DT_BCM_CRC_DA
    DT_DT_BCM_RollingCounter_DA
    DT_DT_BCM_IMU_ACC_x
    DT_DT_BCM_IMU_ACC_y
    DT_DT_BCM_IMU_ACC_z
    DT_DT_BCM_IMU_ACC_Roll_Rate
    DT_DT_BCM_IMU_ACC_Pitch_Rate
    DT_DT_BCM_IMU_ACC_Yaw_Rate
    DT_DT_BCM_IMU_Valid
    DT_DT_ACU_IMU_CRC_15
    DT_DT_ACU_IMU_RollingCounter_15
    DT_DT_ACU_IMU_ACC_x
    DT_DT_ACU_IMU_ACC_y
    DT_DT_ACU_IMU_ACC_z
    DT_DT_ACU_IMU_Roll_Rate
    DT_DT_ACU_IMU_Pitch_Rate
    DT_DT_ACU_IMU_Yaw_Rate
    DT_DT_ACU_IMU_Calibrated
    DT_DT_ACU_IMU_Valid
    DT_DT_ACU_IMU_Fault_Status
    DT_DT_ACU_IMU_MessageStatus
    DT_DT_ACU_IMU_FunctionSafetyStatus
    DT_DT_ACU_IMU_Temperature
    DT_DT_LMC_CRC_133
    DT_DT_LMC_DrvReqTorque
    DT_DT_LMC_RollingCounter_133
    DT_DT_ICU_RollingCounter_5BE
    DT_DT_ICU_Imu_Cal_Staus
    DT_DT_ICU_Imu_Cal_Gyro
    DT_DT_ICU_Imu_Cal_Pitch
    DT_DT_ICU_Imu_Cal_Roll
    DT_DT_BCM_CRC_4A
    DT_DT_BCM_IBCLimphomeSts
    DT_DT_BCM_EOLAutomaticActiveSts_C
    DT_DT_BCM_TorqueLimte
    DT_DT_BCM_RollingCounter_4A
package /MVCU_AutoGenPkg/MVCU/Pck_AutoGen_Sw/Components
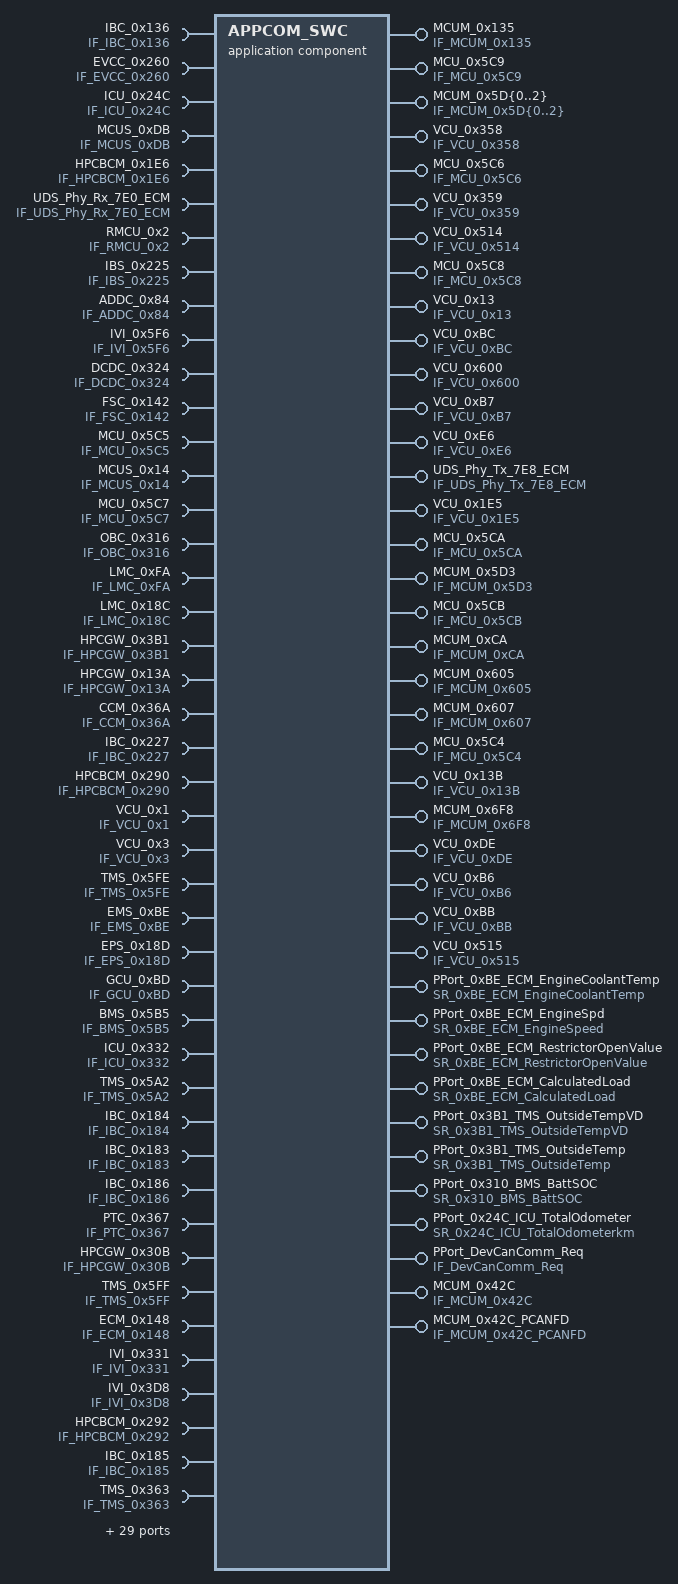
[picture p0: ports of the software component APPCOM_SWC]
  application sw component type APPCOM_SWC
    provide port MCUM_0x135: provided-interface=IF_MCUM_0x135
    4 x require port:
      IBC_0x136: required-interface=IF_IBC_0x136
      EVCC_0x260: required-interface=IF_EVCC_0x260
      ICU_0x24C: required-interface=IF_ICU_0x24C
      MCUS_0xDB: required-interface=IF_MCUS_0xDB
    provide port MCU_0x5C9: provided-interface=IF_MCU_0x5C9
    require port HPCBCM_0x1E6: required-interface=IF_HPCBCM_0x1E6
    require port UDS_Phy_Rx_7E0_ECM: required-interface=IF_UDS_Phy_Rx_7E0_ECM
    4 x provide port:
      MCUM_0x5D{0..2}: provided-interface=IF_MCUM_0x5D{0..2}
      VCU_0x358: provided-interface=IF_VCU_0x358
    6 x require port:
      RMCU_0x2: required-interface=IF_RMCU_0x2
      IBS_0x225: required-interface=IF_IBS_0x225
      ADDC_0x84: required-interface=IF_ADDC_0x84
      IVI_0x5F6: required-interface=IF_IVI_0x5F6
      DCDC_0x324: required-interface=IF_DCDC_0x324
      FSC_0x142: required-interface=IF_FSC_0x142
    provide port MCU_0x5C6: provided-interface=IF_MCU_0x5C6
    7 x require port:
      MCU_0x5C5: required-interface=IF_MCU_0x5C5
      MCUS_0x14: required-interface=IF_MCUS_0x14
      MCU_0x5C7: required-interface=IF_MCU_0x5C7
      OBC_0x316: required-interface=IF_OBC_0x316
      LMC_0xFA: required-interface=IF_LMC_0xFA
      LMC_0x18C: required-interface=IF_LMC_0x18C
      HPCGW_0x3B1: required-interface=IF_HPCGW_0x3B1
    provide port VCU_0x359: provided-interface=IF_VCU_0x359
    provide port VCU_0x514: provided-interface=IF_VCU_0x514
    require port HPCGW_0x13A: required-interface=IF_HPCGW_0x13A
    require port CCM_0x36A: required-interface=IF_CCM_0x36A
    require port IBC_0x227: required-interface=IF_IBC_0x227
    provide port MCU_0x5C8: provided-interface=IF_MCU_0x5C8
    require port HPCBCM_0x290: required-interface=IF_HPCBCM_0x290
    provide port VCU_0x13: provided-interface=IF_VCU_0x13
    7 x require port:
      VCU_0x1: required-interface=IF_VCU_0x1
      VCU_0x3: required-interface=IF_VCU_0x3
      TMS_0x5FE: required-interface=IF_TMS_0x5FE
      EMS_0xBE: required-interface=IF_EMS_0xBE
      EPS_0x18D: required-interface=IF_EPS_0x18D
      GCU_0xBD: required-interface=IF_GCU_0xBD
      BMS_0x5B5: required-interface=IF_BMS_0x5B5
    provide port VCU_0xBC: provided-interface=IF_VCU_0xBC
    6 x require port:
      ICU_0x332: required-interface=IF_ICU_0x332
      TMS_0x5A2: required-interface=IF_TMS_0x5A2
      IBC_0x184: required-interface=IF_IBC_0x184
      IBC_0x183: required-interface=IF_IBC_0x183
      IBC_0x186: required-interface=IF_IBC_0x186
      PTC_0x367: required-interface=IF_PTC_0x367
    provide port VCU_0x600: provided-interface=IF_VCU_0x600
    require port HPCGW_0x30B: required-interface=IF_HPCGW_0x30B
    4 x provide port:
      VCU_0xB7: provided-interface=IF_VCU_0xB7
      VCU_0xE6: provided-interface=IF_VCU_0xE6
      UDS_Phy_Tx_7E8_ECM: provided-interface=IF_UDS_Phy_Tx_7E8_ECM
      VCU_0x1E5: provided-interface=IF_VCU_0x1E5
    10 x require port:
      TMS_0x5FF: required-interface=IF_TMS_0x5FF
      ECM_0x148: required-interface=IF_ECM_0x148
      IVI_0x331: required-interface=IF_IVI_0x331
      IVI_0x3D8: required-interface=IF_IVI_0x3D8
      HPCBCM_0x292: required-interface=IF_HPCBCM_0x292
      IBC_0x185: required-interface=IF_IBC_0x185
      TMS_0x363: required-interface=IF_TMS_0x363
      BMS_0x5B1: required-interface=IF_BMS_0x5B1
      TMS_0x561: required-interface=IF_TMS_0x561
      HPCBCM_0x1E4: required-interface=IF_HPCBCM_0x1E4
    provide port MCU_0x5CA: provided-interface=IF_MCU_0x5CA
    provide port MCUM_0x5D3: provided-interface=IF_MCUM_0x5D3
    require port ECM_0x5EC: required-interface=IF_ECM_0x5EC
    require port ECM_0x147: required-interface=IF_ECM_0x147
    provide port MCU_0x5CB: provided-interface=IF_MCU_0x5CB
    provide port MCUM_0xCA: provided-interface=IF_MCUM_0xCA
    require port IBC_0x182: required-interface=IF_IBC_0x182
    provide port MCUM_0x605: provided-interface=IF_MCUM_0x605
    provide port MCUM_0x607: provided-interface=IF_MCUM_0x607
    require port ICU_0x24D: required-interface=IF_ICU_0x24D
    require port ICU_0x249: required-interface=IF_ICU_0x249
    require port ACU_0x233: required-interface=IF_ACU_0x233
    provide port MCU_0x5C4: provided-interface=IF_MCU_0x5C4
    require port BMS_0x1A1: required-interface=IF_BMS_0x1A1
    require port IBC_0xB1: required-interface=IF_IBC_0xB1
    require port ADDC_0x83: required-interface=IF_ADDC_0x83
    provide port VCU_0x13B: provided-interface=IF_VCU_0x13B
    require port BMS_0x310: required-interface=IF_BMS_0x310
    provide port MCUM_0x6F8: provided-interface=IF_MCUM_0x6F8
    provide port VCU_0xDE: provided-interface=IF_VCU_0xDE
    require port GCU_0x2C1: required-interface=IF_GCU_0x2C1
    provide port VCU_0xB6: provided-interface=IF_VCU_0xB6
    require port HPCBCM_0x291: required-interface=IF_HPCBCM_0x291
    require port ACU_0x2A3: required-interface=IF_ACU_0x2A3
    require port IVI_0x34A: required-interface=IF_IVI_0x34A
    11 x provide port:
      VCU_0xBB: provided-interface=IF_VCU_0xBB
      VCU_0x515: provided-interface=IF_VCU_0x515
      PPort_0xBE_ECM_EngineCoolantTemp: provided-interface=SR_0xBE_ECM_EngineCoolantTemp
      PPort_0xBE_ECM_EngineSpd: provided-interface=SR_0xBE_ECM_EngineSpeed
      PPort_0xBE_ECM_RestrictorOpenValue: provided-interface=SR_0xBE_ECM_RestrictorOpenValue
      PPort_0xBE_ECM_CalculatedLoad: provided-interface=SR_0xBE_ECM_CalculatedLoad
      PPort_0x3B1_TMS_OutsideTempVD: provided-interface=SR_0x3B1_TMS_OutsideTempVD
      PPort_0x3B1_TMS_OutsideTemp: provided-interface=SR_0x3B1_TMS_OutsideTemp
      PPort_0x310_BMS_BattSOC: provided-interface=SR_0x310_BMS_BattSOC
      PPort_0x24C_ICU_TotalOdometer: provided-interface=SR_0x24C_ICU_TotalOdometerkm
      PPort_DevCanComm_Req: provided-interface=IF_DevCanComm_Req
    4 x require port:
      RPort_MILIndicatorStatus: required-interface=IndicatorStatus
      RPort_GetPCANBusOffEvent: required-interface=DiagnosticInfo
      RPort_GetCCANBusOffEvent: required-interface=DiagnosticInfo
      RPort_GetVCUCANBusOffEvent: required-interface=DiagnosticInfo
    provide port MCUM_0x42C: provided-interface=IF_MCUM_0x42C
    provide port MCUM_0x42C_PCANFD: provided-interface=IF_MCUM_0x42C_PCANFD
    8 x require port:
      ICU_0xDF: required-interface=IF_ICU_0xDF
      TMS_0x362: required-interface=IF_TMS_0x362
      ACU_0x15: required-interface=IF_ACU_0x15
      HPCBCM_0xDA: required-interface=IF_HPCBCM_0xDA
      LMC_0x133: required-interface=IF_LMC_0x133
      LMCSSU_0x25A: required-interface=IF_LMCSSU_0x25A
      HPCBCM_0x4A: required-interface=IF_HPCBCM_0x4A
      ICU_0x5BE: required-interface=IF_ICU_0x5BE
